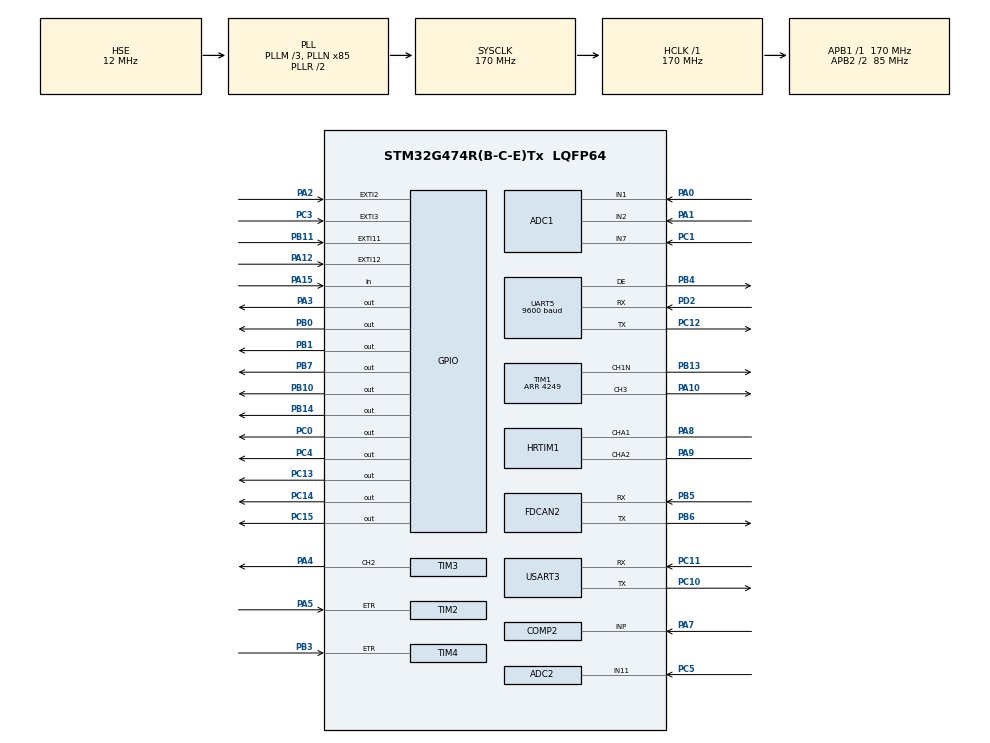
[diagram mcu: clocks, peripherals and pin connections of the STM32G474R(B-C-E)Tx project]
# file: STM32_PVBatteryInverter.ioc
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ADC1.Channel-0\#ChannelRegularConversion=ADC_CHANNEL_1
ADC1.Channel-1\#ChannelRegularConversion=ADC_CHANNEL_7
ADC1.DMAContinuousRequests=ENABLE
ADC1.EOCSelection=ADC_EOC_SEQ_CONV
ADC1.ExternalTrigConv=ADC_EXTERNALTRIG_HRTIM_TRG1
ADC1.NbrOfConversion=2
ADC1.NbrOfConversionFlag=1
ADC1.OffsetNumber-0\#ChannelRegularConversion=ADC_OFFSET_NONE
ADC1.OffsetNumber-1\#ChannelRegularConversion=ADC_OFFSET_NONE
ADC1.Overrun=ADC_OVR_DATA_OVERWRITTEN
ADC1.OversamplingMode=ENABLE
ADC1.Rank-0\#ChannelRegularConversion=1
ADC1.Rank-1\#ChannelRegularConversion=2
ADC1.Ratio=ADC_OVERSAMPLING_RATIO_8
ADC1.RightBitShift=ADC_RIGHTBITSHIFT_3
ADC1.SamplingTime-0\#ChannelRegularConversion=ADC_SAMPLETIME_2CYCLES_5
ADC1.SamplingTime-1\#ChannelRegularConversion=ADC_SAMPLETIME_2CYCLES_5
ADC1.SingleDiff-0\#ChannelRegularConversion=ADC_DIFFERENTIAL_ENDED
ADC1.master=1
ADC2.Channel-0\#ChannelRegularConversion=ADC_CHANNEL_11
ADC2.ClockPrescaler=ADC_CLOCK_SYNC_PCLK_DIV4
ADC2.DMAContinuousRequests=ENABLE
ADC2.ExternalTrigConv=ADC_SOFTWARE_START
ADC2.NbrOfConversion=1
ADC2.NbrOfConversionFlag=1
ADC2.OffsetNumber-0\#ChannelRegularConversion=ADC_OFFSET_NONE
ADC2.Overrun=ADC_OVR_DATA_OVERWRITTEN
ADC2.OversamplingMode=ENABLE
ADC2.Rank-0\#ChannelRegularConversion=1
ADC2.Ratio=ADC_OVERSAMPLING_RATIO_128
ADC2.RightBitShift=ADC_RIGHTBITSHIFT_3
ADC2.SamplingTime-0\#ChannelRegularConversion=ADC_SAMPLETIME_2CYCLES_5
COMP2.TriggerMode=COMP_TRIGGERMODE_IT_FALLING
Dma.ADC1.1.Direction=DMA_PERIPH_TO_MEMORY
Dma.ADC1.1.EventEnable=DISABLE
Dma.ADC1.1.Instance=DMA1_Channel2
Dma.ADC1.1.MemDataAlignment=DMA_MDATAALIGN_HALFWORD
Dma.ADC1.1.MemInc=DMA_MINC_ENABLE
Dma.ADC1.1.Mode=DMA_CIRCULAR
Dma.ADC1.1.PeriphDataAlignment=DMA_PDATAALIGN_HALFWORD
Dma.ADC1.1.PeriphInc=DMA_PINC_DISABLE
Dma.ADC1.1.Polarity=HAL_DMAMUX_REQ_GEN_RISING
Dma.ADC1.1.Priority=DMA_PRIORITY_LOW
Dma.ADC1.1.RequestNumber=1
Dma.ADC1.1.SignalID=NONE
Dma.ADC1.1.SyncEnable=DISABLE
Dma.ADC1.1.SyncPolarity=HAL_DMAMUX_SYNC_NO_EVENT
Dma.ADC1.1.SyncRequestNumber=1
Dma.ADC1.1.SyncSignalID=NONE
Dma.ADC2.0.Direction=DMA_PERIPH_TO_MEMORY
Dma.ADC2.0.EventEnable=DISABLE
Dma.ADC2.0.Instance=DMA1_Channel1
Dma.ADC2.0.MemDataAlignment=DMA_MDATAALIGN_HALFWORD
Dma.ADC2.0.MemInc=DMA_MINC_ENABLE
Dma.ADC2.0.Mode=DMA_CIRCULAR
Dma.ADC2.0.PeriphDataAlignment=DMA_PDATAALIGN_HALFWORD
Dma.ADC2.0.PeriphInc=DMA_PINC_DISABLE
Dma.ADC2.0.Polarity=HAL_DMAMUX_REQ_GEN_RISING
Dma.ADC2.0.Priority=DMA_PRIORITY_LOW
Dma.ADC2.0.RequestNumber=1
Dma.ADC2.0.SignalID=NONE
Dma.ADC2.0.SyncEnable=DISABLE
Dma.ADC2.0.SyncPolarity=HAL_DMAMUX_SYNC_NO_EVENT
Dma.ADC2.0.SyncRequestNumber=1
Dma.ADC2.0.SyncSignalID=NONE
Dma.Request0=ADC2
Dma.Request1=ADC1
Dma.Request2=USART3_TX
Dma.Request3=UART5_TX
Dma.Request4=UART5_RX
Dma.UART5_RX.4.Direction=DMA_PERIPH_TO_MEMORY
Dma.UART5_RX.4.EventEnable=DISABLE
Dma.UART5_RX.4.Instance=DMA1_Channel5
Dma.UART5_RX.4.MemDataAlignment=DMA_MDATAALIGN_BYTE
Dma.UART5_RX.4.MemInc=DMA_MINC_ENABLE
Dma.UART5_RX.4.Mode=DMA_NORMAL
Dma.UART5_RX.4.PeriphDataAlignment=DMA_PDATAALIGN_BYTE
Dma.UART5_RX.4.PeriphInc=DMA_PINC_DISABLE
Dma.UART5_RX.4.Polarity=HAL_DMAMUX_REQ_GEN_RISING
Dma.UART5_RX.4.Priority=DMA_PRIORITY_LOW
Dma.UART5_RX.4.RequestNumber=1
Dma.UART5_RX.4.SignalID=NONE
Dma.UART5_RX.4.SyncEnable=DISABLE
Dma.UART5_RX.4.SyncPolarity=HAL_DMAMUX_SYNC_NO_EVENT
Dma.UART5_RX.4.SyncRequestNumber=1
Dma.UART5_RX.4.SyncSignalID=NONE
Dma.UART5_TX.3.Direction=DMA_MEMORY_TO_PERIPH
Dma.UART5_TX.3.EventEnable=DISABLE
Dma.UART5_TX.3.Instance=DMA1_Channel4
Dma.UART5_TX.3.MemDataAlignment=DMA_MDATAALIGN_BYTE
Dma.UART5_TX.3.MemInc=DMA_MINC_ENABLE
Dma.UART5_TX.3.Mode=DMA_NORMAL
Dma.UART5_TX.3.PeriphDataAlignment=DMA_PDATAALIGN_BYTE
Dma.UART5_TX.3.PeriphInc=DMA_PINC_DISABLE
Dma.UART5_TX.3.Polarity=HAL_DMAMUX_REQ_GEN_RISING
Dma.UART5_TX.3.Priority=DMA_PRIORITY_LOW
Dma.UART5_TX.3.RequestNumber=1
Dma.UART5_TX.3.SignalID=NONE
Dma.UART5_TX.3.SyncEnable=DISABLE
Dma.UART5_TX.3.SyncPolarity=HAL_DMAMUX_SYNC_NO_EVENT
Dma.UART5_TX.3.SyncRequestNumber=1
Dma.UART5_TX.3.SyncSignalID=NONE
Dma.USART3_TX.2.Direction=DMA_MEMORY_TO_PERIPH
Dma.USART3_TX.2.EventEnable=DISABLE
Dma.USART3_TX.2.Instance=DMA1_Channel3
Dma.USART3_TX.2.MemDataAlignment=DMA_MDATAALIGN_BYTE
Dma.USART3_TX.2.MemInc=DMA_MINC_ENABLE
Dma.USART3_TX.2.Mode=DMA_NORMAL
Dma.USART3_TX.2.PeriphDataAlignment=DMA_PDATAALIGN_BYTE
Dma.USART3_TX.2.PeriphInc=DMA_PINC_DISABLE
Dma.USART3_TX.2.Polarity=HAL_DMAMUX_REQ_GEN_RISING
Dma.USART3_TX.2.Priority=DMA_PRIORITY_LOW
Dma.USART3_TX.2.RequestNumber=1
Dma.USART3_TX.2.SignalID=NONE
Dma.USART3_TX.2.SyncEnable=DISABLE
Dma.USART3_TX.2.SyncPolarity=HAL_DMAMUX_SYNC_NO_EVENT
Dma.USART3_TX.2.SyncRequestNumber=1
Dma.USART3_TX.2.SyncSignalID=NONE
FDCAN2.CalculateBaudRateNominal=500000
FDCAN2.CalculateTimeBitNominal=2000
FDCAN2.CalculateTimeQuantumNominal=400.0
FDCAN2.Mode=FDCAN_MODE_NORMAL
FDCAN2.NominalPrescaler=68
FDCAN2.StdFiltersNbr=2
HRTIM1.ADCTrigger1_Source1=HRTIM_ADCTRIGGEREVENT13_TIMERA_CMP3
HRTIM1.ADCTrigger_Id1=HRTIM_ADCTRIGGER_1
HRTIM1.Adrom_TA=HRTIM_TIM_ADROM_CREST
HRTIM1.CompareUnit1-Output_TA1TA2=HRTIM_COMPAREUNIT_1
HRTIM1.CompareUnit3-Output_TA1TA2=HRTIM_COMPAREUNIT_3
HRTIM1.CompareValue1-Output_TA1TA2=4250
HRTIM1.CompareValue3-Output_TA1TA2=8020
HRTIM1.Configuration_TA=Waveform
HRTIM1.Deadtimeconfig-Output_TA1TA2=__NULL
HRTIM1.Event_EEV1=__NULL
HRTIM1.GreaterCMP1_TA=HRTIM_TIMERGTCMP1_EQUAL
HRTIM1.GreaterCMP3_TA=HRTIM_TIMERGTCMP3_EQUAL
HRTIM1.NumberADCTriggerSource1=1
HRTIM1.NumberResetSource1-Output_TA1TA2=0
HRTIM1.NumberResetSource2_TA=0
HRTIM1.NumberSetSource1-Output_TA1TA2=1
HRTIM1.NumberSetSource2_TA=1
HRTIM1.Outrom_TA=HRTIM_TIM_OUTROM_BOTH
HRTIM1.Periode_TA=8500
HRTIM1.Polarity1-Output_TA1TA2=HRTIM_OUTPUTPOLARITY_LOW
HRTIM1.Polarity2-Output_TA1TA2=HRTIM_OUTPUTPOLARITY_HIGH
HRTIM1.PreloadEnable-Output_TA1TA2=HRTIM_PRELOAD_ENABLED
HRTIM1.PrescalerRatio_TA=HRTIM_PRESCALERRATIO_MUL2
HRTIM1.ReSyncUpdate-Output_TA1TA2=HRTIM_TIMERESYNC_UPDATE_CONDITIONAL
HRTIM1.RepetitionUpdate-Output_TA1TA2=HRTIM_UPDATEONREPETITION_ENABLED
HRTIM1.SetOutput1_Source1-Output_TA1TA2=HRTIM_OUTPUTSET_TIMCMP1
HRTIM1.SetOutput2_Source1-Output_TA1TA2=HRTIM_OUTPUTSET_TIMCMP1
HRTIM1.UpDownMode-Output_TA1TA2=HRTIM_TIMERUPDOWNMODE_UPDOWN
HRTIM1.postscaler1=0x0
HRTIM1.rom_TA=HRTIM_TIM_ROM_BOTH
IWDG.Prescaler=IWDG_PRESCALER_8
LPTIM1.ClockPrescaler=LPTIM_PRESCALER_DIV128
Mcu.Family=STM32G4
Mcu.Name=STM32G474R(B-C-E)Tx
Mcu.Package=LQFP64
NVIC.ADC1_2_IRQn=true\:0\:0\:false\:false\:true\:true\:true\:true
NVIC.COMP1_2_3_IRQn=true\:0\:0\:false\:false\:true\:false\:true\:true
NVIC.DMA1_Channel1_IRQn=true\:0\:0\:false\:false\:true\:false\:true\:true
NVIC.DMA1_Channel2_IRQn=true\:0\:0\:false\:false\:true\:false\:true\:true
NVIC.DMA1_Channel3_IRQn=true\:5\:0\:true\:false\:true\:false\:true\:true
NVIC.DMA1_Channel4_IRQn=true\:5\:0\:true\:false\:true\:false\:true\:true
NVIC.DMA1_Channel5_IRQn=true\:5\:0\:true\:false\:true\:false\:true\:true
NVIC.EXTI15_10_IRQn=true\:0\:0\:false\:false\:true\:true\:true\:true
NVIC.EXTI2_IRQn=true\:0\:0\:false\:false\:true\:true\:true\:true
NVIC.EXTI3_IRQn=true\:0\:0\:false\:false\:true\:true\:true\:true
NVIC.FDCAN2_IT0_IRQn=true\:4\:0\:true\:false\:true\:true\:true\:true
NVIC.FDCAN2_IT1_IRQn=true\:4\:0\:true\:false\:true\:true\:true\:true
NVIC.LPTIM1_IRQn=true\:5\:0\:true\:false\:true\:true\:true\:true
NVIC.PriorityGroup=NVIC_PRIORITYGROUP_4
NVIC.TIM1_TRG_COM_TIM17_IRQn=true\:0\:0\:false\:false\:true\:true\:true\:true
NVIC.UART5_IRQn=true\:4\:0\:true\:false\:true\:true\:true\:true
NVIC.USART3_IRQn=true\:4\:0\:true\:false\:true\:true\:true\:true
PA0.Mode=IN1-Differential
PA0.Signal=ADC1_IN1
PA1.Mode=IN1-Differential
PA1.Signal=ADC1_IN2
PA10.Signal=S_TIM1_CH3
PA11.Signal=FDCAN1_RX
PA12.GPIO_ModeDefaultEXTI=GPIO_MODE_IT_RISING
PA12.GPIO_PuPd=GPIO_PULLUP
PA12.Signal=GPXTI12
PA13.Mode=Serial_Wire
PA13.Signal=SYS_JTMS-SWDIO
PA14.Mode=Serial_Wire
PA14.Signal=SYS_JTCK-SWCLK
PA15.GPIO_PuPd=GPIO_PULLDOWN
PA15.Signal=GPIO_Input
PA2.GPIO_ModeDefaultEXTI=GPIO_MODE_IT_FALLING
PA2.Signal=GPXTI2
PA3.Signal=GPIO_Output
PA4.Signal=S_TIM3_CH2
PA5.Signal=S_TIM2_ETR
PA6.Signal=ADC2_IN3
PA7.Mode=INP
PA7.Signal=COMP2_INP
PA8.Mode=Output_TA1TA2
PA8.Signal=HRTIM1_CHA1
PA9.Mode=Output_TA1TA2
PA9.Signal=HRTIM1_CHA2
PB0.Signal=GPIO_Output
PB1.Signal=GPIO_Output
PB10.Signal=GPIO_Output
PB11.GPIO_ModeDefaultEXTI=GPIO_MODE_IT_RISING
PB11.GPIO_PuPd=GPIO_PULLUP
PB11.Signal=GPXTI11
PB13.Mode=PWM Generation1 CH1N
PB13.Signal=TIM1_CH1N
PB14.Signal=GPIO_Output
PB15.Signal=TIM1_CH3N
PB2.Signal=ADC2_IN12
PB3.Signal=S_TIM4_ETR
PB4.Mode=Hardware Flow Control (RS485)
PB4.Signal=UART5_DE
PB5.Mode=FDCAN_Activate
PB5.Signal=FDCAN2_RX
PB6.Mode=FDCAN_Activate
PB6.Signal=FDCAN2_TX
PB7.Signal=GPIO_Output
PB9.Signal=FDCAN1_TX
PC0.Signal=GPIO_Output
PC1.Mode=IN7-Single-Ended
PC1.Signal=ADC1_IN7
PC10.Mode=Asynchronous
PC10.Signal=USART3_TX
PC11.Mode=Asynchronous
PC11.Signal=USART3_RX
PC12.Mode=Asynchronous
PC12.Signal=UART5_TX
PC13.Signal=GPIO_Output
PC14-OSC32_IN.Signal=GPIO_Output
PC15-OSC32_OUT.Signal=GPIO_Output
PC3.GPIO_ModeDefaultEXTI=GPIO_MODE_IT_FALLING
PC3.Signal=GPXTI3
PC4.Signal=GPIO_Output
PC5.Mode=IN11-Single-Ended
PC5.Signal=ADC2_IN11
PC6.Signal=HRTIM1_CHF1
PC7.Signal=HRTIM1_CHF2
PC8.Signal=HRTIM1_CHE1
PC9.Signal=HRTIM1_CHE2
PD2.Mode=Asynchronous
PD2.Signal=UART5_RX
PF0-OSC_IN.Mode=HSE-External-Oscillator
PF0-OSC_IN.Signal=RCC_OSC_IN
PF1-OSC_OUT.Mode=HSE-External-Oscillator
PF1-OSC_OUT.Signal=RCC_OSC_OUT
ProjectManager.HeapSize=0x200
ProjectManager.StackSize=0x400
ProjectManager.TargetToolchain=STM32CubeIDE
RCC.ADC12Freq_Value=170000000
RCC.ADC345Freq_Value=170000000
RCC.AHBFreq_Value=170000000
RCC.APB1Freq_Value=170000000
RCC.APB1TimFreq_Value=170000000
RCC.APB2CLKDivider=RCC_HCLK_DIV2
RCC.APB2Freq_Value=85000000
RCC.APB2TimFreq_Value=170000000
RCC.CortexFreq_Value=170000000
RCC.EXTERNAL_CLOCK_VALUE=12288000
RCC.HCLKFreq_Value=170000000
RCC.HSE_VALUE=12000000
RCC.HSI48_VALUE=48000000
RCC.HSI_VALUE=16000000
RCC.LPTIM1CLockSelection=RCC_LPTIM1CLKSOURCE_LSI
RCC.LSE_VALUE=32768
RCC.PLLM=RCC_PLLM_DIV3
RCC.PLLN=85
RCC.PLLSourceVirtual=RCC_PLLSOURCE_HSE
RCC.SYSCLKFreq_VALUE=170000000
RCC.SYSCLKSource=RCC_SYSCLKSOURCE_PLLCLK
RCC.USBFreq_Value=170000000
RCC.VCOOutputFreq_Value=340000000
SH.S_TIM1_CH3.0=TIM1_CH3,PWM Generation3 CH3
SH.S_TIM2_ETR.0=TIM2_ETR,ClockSourceETR_Mode2
SH.S_TIM3_CH2.0=TIM3_CH2,PWM Generation2 CH2
SH.S_TIM4_ETR.0=TIM4_ETR,ClockSourceETR_Mode2
TIM1.Channel-PWM\ Generation1\ CH1N=TIM_CHANNEL_1
TIM1.Channel-PWM\ Generation3\ CH3=TIM_CHANNEL_3
TIM1.CounterMode=TIM_COUNTERMODE_CENTERALIGNED1
TIM1.OCNPolarity_1=TIM_OCNPOLARITY_LOW
TIM1.PeriodNoDither=4249
TIM1.RepetitionCounter=1
TIM1.TIM_MasterOutputTrigger=TIM_TRGO_UPDATE
TIM3.Channel-PWM\ Generation1\ CH1=TIM_CHANNEL_1
TIM3.Channel-PWM\ Generation2\ CH2=TIM_CHANNEL_2
UART5.BaudRate=9600
UART5.FIFOMode=FIFOMODE_ENABLE
UART5.RXFIFOThreshold=RXFIFO_THRESHOLD_1QUARTERFULL
UART5.TXFIFOThreshold=TXFIFO_THRESHOLD_1EIGHTHFULL
USART3.FIFOMode=FIFOMODE_ENABLE
USART3.VirtualMode-Asynchronous=VM_ASYNC
VP_COMP2_VS_VREFINT.Mode=VREFINT
VP_IWDG_VS_IWDG.Mode=IWDG_Activate
VP_LPTIM1_VS_LPTIM_counterModeInternalClock.Mode=Counts__internal_clock_event_00
VP_SYS_VS_DBSignals.Mode=DisableDeadBatterySignals
board=custom

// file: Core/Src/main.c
/* USER CODE BEGIN Header */
/**
  ******************************************************************************
  * @file           : main.c
  * @brief          : Main program body
  ******************************************************************************
  * @attention
  *
  * Copyright (c) 2023 STMicroelectronics.
  * All rights reserved.
  *
  * This software is licensed under terms that can be found in the LICENSE file
  * in the root directory of this software component.
  * If no LICENSE file comes with this software, it is provided AS-IS.
  *
  ******************************************************************************
  */
/* USER CODE END Header */
#include "main.h"

/* USER CODE BEGIN Includes */
#include <stdlib.h>
#include <stdbool.h>
#include <stdio.h>

#include <string.h>

#include "common.h"
#include "monitoring.h"
#include "gpio.h"
#include "can_bus.h"
#include "ac_control.h"
#include "dc_control.h"
#include "sys_mode_controller.h"
#include "BatteryManagement/bms_types.h"
#include "electricity_meter.h"
#include "power_controller.h"
#include "battery.h"
#include <sml/sml_crc16.h>
#include <modbus_hybridinverter.h>

// todo
typedef struct {
    uint16_t cell_voltage_max_mV;
    uint16_t cell_voltage_max_index;
    uint16_t cell_voltage_min_mV;
    uint16_t cell_voltage_min_index;
} __attribute__((__packed__)) csc_cell_volt_min_max_t;

/* USER CODE END Includes */

/* USER CODE BEGIN PD */
#define uSend(x) uartSend((char *)x, sizeof x -1)
/* USER CODE END PD */

ADC_HandleTypeDef hadc1;
ADC_HandleTypeDef hadc2;
DMA_HandleTypeDef hdma_adc1;
DMA_HandleTypeDef hdma_adc2;

COMP_HandleTypeDef hcomp2;

FDCAN_HandleTypeDef hfdcan2;

HRTIM_HandleTypeDef hhrtim1;

IWDG_HandleTypeDef hiwdg;

LPTIM_HandleTypeDef hlptim1;

TIM_HandleTypeDef htim1;
TIM_HandleTypeDef htim2;
TIM_HandleTypeDef htim3;
TIM_HandleTypeDef htim4;

UART_HandleTypeDef huart5;
UART_HandleTypeDef huart3;
DMA_HandleTypeDef hdma_uart5_tx;
DMA_HandleTypeDef hdma_uart5_rx;
DMA_HandleTypeDef hdma_usart3_tx;

/* USER CODE BEGIN PV */
char tx_buf[64];
uint8_t tx_len;

UART_HandleTypeDef* huart_rs485;
UART_HandleTypeDef* huart_debug;
mbus_t modbus;

uint16_t ADC1ConvertedData[2];
uint16_t ADC2ConvertedData[1];
volatile uint16_t debug_sigma_delta_re;

volatile uint16_t id;
control_ref_t ctrl_ref;
volatile bool print_request;

volatile uint32_t cnt_1Hz;
volatile uint32_t cntErr_1Hz;

volatile uint16_t debug_v_dc_FBboost_sincfilt_100mV;
volatile uint16_t debug_v_dc_FBgrid_sincfilt_100mV;

extern volatile int16_t debug_v_ac_rms_100mV;
#if SENSOR_CALIBRATION_MODE == 1
extern volatile int16_t debug_v_ac_100mV;
extern volatile int16_t debug_i_ac_10mA;
volatile int16_t debug_i_dc_filt_10mA;
#endif //SENSOR_CALIBRATION_MODE

extern volatile int16_t debug_i_ac_ref_amp_10mA;

uint8_t ubKeyNumber = 0x0;

/* USER CODE END PV */

void SystemClock_Config(void);
static void MX_GPIO_Init(void);
static void MX_DMA_Init(void);
static void MX_ADC1_Init(void);
static void MX_ADC2_Init(void);
static void MX_FDCAN2_Init(void);
static void MX_HRTIM1_Init(void);
static void MX_TIM1_Init(void);
static void MX_TIM2_Init(void);
static void MX_TIM3_Init(void);
static void MX_TIM4_Init(void);
static void MX_UART5_Init(void);
static void MX_USART3_UART_Init(void);
static void MX_IWDG_Init(void);
static void MX_LPTIM1_Init(void);
static void MX_COMP2_Init(void);
/* USER CODE BEGIN PFP */
static void FDCAN_Config(void);

/* USER CODE END PFP */

/* USER CODE BEGIN 0 */

void uartSend(char* ptr, int len)
{
    HAL_UART_Transmit(huart_debug, (uint8_t *)ptr,len, 10);
}

void uSendInt(int value)
{
	itoa(value, tx_buf, 10);
	tx_len=strlen(tx_buf);
	HAL_UART_Transmit(huart_debug, (uint8_t *)tx_buf, tx_len, 10);
}

void uSend_1m(int int_value)
{
	float value = int_value/1000.0;
	tx_len = snprintf(NULL, 0, "%.03f", value);
	char *str = (char *)malloc(tx_len + 1);
	snprintf(str, tx_len + 1, "%f.03", value);
	HAL_UART_Transmit(huart_debug, (uint8_t *)str, tx_len, 10);
	free(str);
}

void uSend_10m(int int_value)
{
	float value = int_value/100.0;
	tx_len = snprintf(NULL, 0, "%.02f", value);
	char *str = (char *)malloc(tx_len + 1);
	snprintf(str, tx_len + 1, "%f.02", value);
	HAL_UART_Transmit(huart_debug, (uint8_t *)str, tx_len, 10);
	free(str);
}

void uSend_100m(int int_value)
{
	float value = int_value/10.0;
	tx_len = snprintf(NULL, 0, "%.01f", value);
	char *str = (char *)malloc(tx_len + 1);
	snprintf(str, tx_len + 1, "%f.01", value);
	HAL_UART_Transmit(huart_debug, (uint8_t *)str, tx_len, 10);
	free(str);
}

int mbus_send(const mbus_t context, const uint8_t* data, const uint16_t size)
{
	// V1: blocking during send
	//HAL_Delay(1);
	if (HAL_UART_Transmit( huart_rs485, (uint8_t*) data, size, 1000) == HAL_OK) {
		return size;
	}

	// V2: use DMA
//	if (HAL_UART_Transmit_DMA( huart_rs485, (uint8_t*) data, size) == HAL_OK) {
//		return size;
//	}

	return 0;
}

void resetWatchdog()
{
	// Watchdog runs at 32/8=4kHz -> ~1sec for 4095
    /* Refresh IWDG: reload counter */
    if(HAL_IWDG_Refresh(&hiwdg) != HAL_OK) {
      /* Refresh Error */
      Error_Handler();
    }
}

void HAL_LPTIM_AutoReloadMatchCallback(LPTIM_HandleTypeDef *hlptim)
{
	cnt_1Hz++;
	if (get_sys_errorcode() != EC_NO_ERROR) {
		cntErr_1Hz++;
	}
}

void fill_monitor_vars_sys(monitor_vars_t* mon_vars)
{
	mon_vars->id = id;
	mon_vars->sys_mode = get_sys_mode();
	mon_vars->sys_errcode = get_sys_errorcode();

	fill_monitor_vars_dc(mon_vars);
	fill_monitor_vars_ac(mon_vars);

	mon_vars->ctrl_mode_AC = ctrl_ref.mode;
	mon_vars->p_ac_ref = ctrl_ref.p_ac_rms;

#if SYSTEM_HAS_BATTERY == 1
	const batteryStatus_t* battery = get_batteryStatus();
	mon_vars->bat_p = battery->power_W;
	mon_vars->soc_10mPercent = battery->soc_percent*100;
#endif //SYSTEM_HAS_BATTERY
}

#if COMM_READ_ELECTRICITY_METER == 1
// sends monitor_vars + header + crc via RS485
static void send_inverterdata()
{
	// if BMS is not part of the bus, add: Struct BMS Data : onoff Soc V I vmin vmax

	static monitor_packet_t mon_packet = {.header=0xDEADBEEF, 0};  // static for DMA
	fill_monitor_vars_sys(&mon_packet.monitor_vars);

	mon_packet.crc = sml_crc16_calculate((uint8_t *)&mon_packet.monitor_vars, sizeof(mon_packet.monitor_vars));

	if (HAL_UART_Transmit(huart_rs485, (uint8_t *)&mon_packet, sizeof(mon_packet), 10) != HAL_OK) {
		Error_Handler();
	}
//	if (HAL_UART_Transmit_DMA(huart_rs485, (uint8_t *)&mon_vars_snapshot, sizeof(mon_vars_snapshot)) != HAL_OK) {
//		Error_Handler();
//	}
}
#endif

void reinitUART(UART_HandleTypeDef *huart, uint32_t BaudRate)
{
	if (huart->Init.BaudRate != BaudRate) {
		huart->Init.BaudRate = BaudRate;
		if (HAL_UARTEx_DisableFifoMode(huart) != HAL_OK) {
			Error_Handler();
		}
		if (HAL_UART_Init(huart) != HAL_OK) {
			Error_Handler();
		}
		if (HAL_UARTEx_EnableFifoMode(huart) != HAL_OK) {
			Error_Handler();
		}
	}
}

void shutdownAll()
{
	gatedriverAC(0);
	gatedriverDC(0);
	contactorAC(0);
	contactorBattery(0);
#if SYSTEM_HAS_BATTERY == 1
	battery_state_request(CMD_BAT_OFF);  // todo: check CMD_BMS_OFF__BAT_OFF
#endif //SYSTEM_HAS_BATTERY
}

int el_meter_status;

void calc_and_wait(uint32_t delay)
{
	resetWatchdog();
	calc_async_dc_control();

#if COMM_READ_ELECTRICITY_METER == 0
	for (uint32_t i=0; i<delay; i++) {
		calc_async_dc_control();
		if (!monitoring_binary_en) {
			HAL_Delay(1);  //ms
		}
	}
#endif

#if COMM_READ_ELECTRICITY_METER == 1
	if (!monitoring_binary_en) {  // smart meter polling read takes too much time
		reinitUART(huart_rs485, 9600);
		resetWatchdog();
#define DUMMY_METER 0
#if DUMMY_METER == 1
		int el_meter_status = EL_METER_OKAY;
#else
		el_meter_status = electricity_meter_read(huart_rs485);
#endif //DUMMY_METER
		//HAL_UART_Abort_IT(&huart1);
		if ( el_meter_status == EL_METER_OKAY) {
			ctrl_ref.p_pcc_prev = ctrl_ref.p_pcc;
#if DUMMY_METER == 1
			const batteryStatus_t* battery = get_batteryStatus();
			//ctrl_ref.p_pcc = 50+battery->power_W;  // p_bat negative is discharging AC 4sec on 4sec off
			//ctrl_ref.p_pcc = 500;  // simulate load
			ctrl_ref.p_pcc = -100;  // simulate PV feedin
#else
			ctrl_ref.p_pcc = electricity_meter_get_power();
#endif //DUMMY_METER
#if SYSTEM_HAS_BATTERY == 1
			ctrl_ref.p_ac_pccCtrl = power_controller_step(modbus_reg_rw.p_pcc_ref_W, ctrl_ref.p_pcc, get_p_ac_max());
#endif //SYSTEM_HAS_BATTERY
		} else if (el_meter_status == EL_METER_CONN_ERR ) {
			ctrl_ref.p_ac_pccCtrl = 0;
		}

		if (el_meter_status == EL_METER_OKAY || el_meter_status == EL_METER_CONN_ERR ) {
			reinitUART(huart_rs485, 115200);
			calc_async_dc_control();

			if (async_battery_communication()) {
				send_inverterdata();

				// receive commands from external energy management system
//#define RX_MAX_CMD_LEN (sizeof("p_bat_chg_max65535\n")+5)
#define RX_MAX_CMD_LEN (sizeof(modbus_reg_rw_t)+8)
				uint8_t rx_buf[RX_MAX_CMD_LEN];

				for (uint16_t i = 0; i < 10; i++) {
					uint16_t rx_len = 0;
					HAL_UARTEx_ReceiveToIdle(huart_rs485, rx_buf, RX_MAX_CMD_LEN, &rx_len, 10);  // 10 x 10ms rx window

					for (uint16_t j = 0; j < rx_len; j++) {
						mbus_poll(modbus, rx_buf[j]);
					}
				}
				apply_sys_mode_cmd(&ctrl_ref);
				mbus_flush(modbus);  // reset incomplete messages
			}
		}
	} else {
		reinitUART(huart_rs485, 115200);
		resetWatchdog();
		calc_async_dc_control();
		async_battery_communication();
	}
#endif //COMM_READ_ELECTRICITY_METER

	calc_p_ac(&ctrl_ref);

	resetWatchdog();
	async_monitor_check(huart_debug);
}

// +-50A sensor range with 3.3V ADC:
// −62.1A to +32.1A
// analog watchdog: (dont use filtering in AWD1 because it does not work with sequence mode (scan conversion))
// oversampling is enabled (8xOSR; 3bit shift -> 4-(log2(8)/3 -1) = 4bit shift down
#define I_AC_AWD_THRESHOLD_HIGH ((E_I_AC_PULSE_MAX_AMP_10mA/IAC_RAW_TO_10mA + IAC_OFFSET_RAW)/16)
#define I_AC_AWD_THRESHOLD_LOW ((-E_I_AC_PULSE_MAX_AMP_10mA/IAC_RAW_TO_10mA + IAC_OFFSET_RAW)/16)
// for test
//#define I_AC_AWD_THRESHOLD_HIGH 208  // +16.0Ampere -> 1600/IAC_RAW_TO_10mA + 2632 = 3327 /16
//#define I_AC_AWD_THRESHOLD_LOW 121  // -16.0Ampere -> -1600/IAC_RAW_TO_10mA + 2632 = 1937 /16
//#define I_AC_AWD_THRESHOLD_HIGH 167  // +1.0Ampere -> 100/IAC_RAW_TO_10mA + 2632 = 2675 /16
//#define I_AC_AWD_THRESHOLD_LOW 162  // -1.0Ampere -> -100/IAC_RAW_TO_10mA + 2632 = 2589 /16
void HAL_ADC_LevelOutOfWindowCallback(ADC_HandleTypeDef* hadc)
{
	shutdownAll();
	set_sys_errorcode(EC_I_AC_PULSE_MAX);
}

void configure_analog_watchdog()
{
	/* Set ADC analog watchdog channels to be monitored */
	LL_ADC_SetAnalogWDMonitChannels(ADC1, LL_ADC_AWD1, LL_ADC_AWD_CHANNEL_7_REG);

	/* Set ADC analog watchdog thresholds */
	LL_ADC_ConfigAnalogWDThresholds(ADC1, LL_ADC_AWD1, I_AC_AWD_THRESHOLD_HIGH, I_AC_AWD_THRESHOLD_LOW);

	/*## Configuration of ADC interruptions ####################################*/
	// ADC1_2 interrupts are enabled in GUI
	/* Enable ADC analog watchdog 1 interruption */
	LL_ADC_EnableIT_AWD1(ADC1);
	LL_ADC_ClearFlag_AWD1(ADC1);
}

void HAL_ADC_ConvCpltCallback(ADC_HandleTypeDef *hadc)
{
	uint32_t start_ISR_cycles = DWT->CYCCNT;
	//static volatile uint16_t vdc_sinc_mix_100mV;
	static volatile uint16_t cnt20kHz_20ms = 0;

	/********************************************************/
	/* Highest priority: Grid control						*/
	/* 	execution rate: 20kHz								*/
	/* 	runtime: max18.4us									*/
	/*  max possible runtime without compare unit 3 change: */
	/*  25-5.1=19.9us										*/
	/********************************************************/

	// ADC1: two channels, Vac and i_ac
	// HRTIM1 triggers ADC once per period and DMA calls this callback if ADC1ConvertedData[2] is full
	// Thus, both channels in ADC1ConvertedData are updated in every call.
	if (hadc == &hadc1) {
		DEBUG_ISR GPIOC->BSRR = (1<<4);  // set Testpin TP201 PC4  T1
		// With 4xOversampling: 4.3us-0.44us=3.9us after mid of PWM period (see documentation/img folder)
		// With 8xOversampling: 7.0us-0.44us=6.6us after mid of PWM period -> 25-6.6=18.4us for calculation

		// start ADC2 conversion, because ADC1 conversions are complete here and can't be disturbed by ADC2
		LL_ADC_REG_StartConversion(hadc2.Instance);

//		if (fast_mon_vars_trig) {
//			if (frame_nr < FAST_MON_FRAMES) {
//				fast_monitor_vars[frame_nr].v_ac_100mV = ADC1ConvertedData[0];
//				fast_monitor_vars[frame_nr].i_ac_10mA = ADC1ConvertedData[1];
//				fast_monitor_vars[frame_nr].i_ac_ref_amp_10mA = ADC2ConvertedData[0]/16;
//				frame_nr++;
//			}
//		}

		measVdcFBgrid();  // if runtime becomes critical, run this line after ac dutycycle calculation

//#define V_AC_CALIB_OFFSET 1979 // Vin=0V offset=0.13V; Vin=313Vsine offset=0.87V
#define V_AC_CALIB_OFFSET 1982 // Vin=0V offset=-0.41V; Vin=313Vsine offset=0.1V
#define V_AC_CALIB_GAIN_PER_MIL 992
// 18.05.2026 Fluke multimeter
// V_AC_CALIB_OFFSET=1982  V_AC_CALIB_GAIN_PER_MIL=989
// 350.4V  shown as  349.1V to  349.3V
// -350.4V shown as -348.2V to -349.7V

		int v_ac_raw_no_calib = ADC1ConvertedData[0];
		int16_t v_ac_raw = ((v_ac_raw_no_calib-V_AC_CALIB_OFFSET)*V_AC_CALIB_GAIN_PER_MIL)/1000;

		//debug_v_ac_100mV = acControl_RAW_to_100mV(v_ac_raw);

		uint16_t i_ac_raw = ADC1ConvertedData[1];
		// Lowpass filter for Ig
//			static uint16_t Ig_prev[3] = {0};
//			uint16_t Ig_filt = lowpass4(i_ac_raw, Ig_prev);
		//debug_Ig_raw_filt = Ig_filt;

		uint16_t v_dc_FBboost_sincfilt_100mV = get_v_dc_FBboost_sincfilt_100mV();
		uint16_t v_dc_FBboost_filt50Hz_100mV = get_v_dc_FBboost_filt50Hz_100mV();
		int16_t duty = acControlStep(cnt20kHz_20ms, ctrl_ref, v_dc_FBboost_sincfilt_100mV, v_dc_FBboost_filt50Hz_100mV, v_ac_raw, i_ac_raw);
#if PWM_TEST_MODE == 1
		fan_control_test(1);
		duty = 4250;  // 50%
		//duty = 150;  // fixed duty for timing alignment test
		gatedriverAC(1);
#endif //PWM_TEST_MODE

		// set the PWM duty cycle value (into a 'shadow register')
		__HAL_HRTIM_SETCOMPARE(&hhrtim1, HRTIM_TIMERINDEX_TIMER_A, HRTIM_COMPAREUNIT_1, duty);

		// copy the PWM duty cycle value from the 'shadow register' to the 'active register' -> done by hardware
		//HAL_HRTIM_SoftwareUpdate(&hhrtim1, HRTIM_TIMERUPDATE_A);
		DEBUG_ISR GPIOC->BRR = (1<<4);  // reset Testpin TP201 PC4  T2: max18.2us after T1 (during meas of T2-T3 ~17.0us)

		/****************************************************/
		/* Lower priority: regular error checking			*/
		/* 	current errors are checked by analog watchdog 	*/
		/* 	execution rate: 40kHz							*/
		/* 	runtime in normal operation: ~2.1us				*/
		/* 	runtime in error case: ~3.1us					*/
		/****************************************************/
		checkErrors();
		static uint32_t blankingCnt = 0;

		if (blankingCnt > 240) {  // dont check sigmadelta data during startup for 240/20kHz/3ADCs = 4ms
			errorPVBI_t limitErr = checkDCLimits();
			if (limitErr != EC_NO_ERROR) {
				shutdownAll();
				set_sys_errorcode(limitErr);
			}
			limitErr = checkACLimits();
			if (limitErr != EC_NO_ERROR) {
				shutdownAll();  // todo shutdown AC only
				set_sys_errorcode(limitErr);
			}
		} else {
			blankingCnt++;
		}

		/********************************************/
		/* Lowest priority: DC stage control		*/
		/* 	DC voltage regulation and MPP tracking	*/
		/* 	runtime: ~5.8 to 8.9us					*/
		/********************************************/

		// 128x oversampling takes 128x(2.5+12.5) @ 170/4=42.5MHz -> 45.18us
		//if (hadc == &hadc2) {  // we take the most recent conversion of ADC2; timing alignment is not critical
		// called with f=40kHz when repetition counter = 0 -> for double current sense
		// called with f=20kHz when repetition counter = 1 -> for single current sense or hardware oversampling
		//
		// In interleaved DCDC booster with diodes, discontinuous current can occur -> Sampling the whole period is necessary
		// fadc = 170MHz/4 = 42.5MHz
		// cycles = 2.5+12.5 = 15
		// fsample = 42.5MHz/15 = 2.833Msamples/s
		// oversampling 128 -> 22.135kHz
		// todo: 22kHz vs 20kHz : no exact average current, but robust for MPPT and much better in discontinuous mode than double sample
		//	update: reduced analog filter BW to 7kHz, thus, discontinuous current should be filtered already in the analog domain
		//	update 25.11.2025: reduced analog filter BW to 1.26kHz
		DEBUG_ISR GPIOC->BSRR = (1<<4);  // set Testpin TP201 PC4  T3: ~19.1us after T1

		measVdcFBboost();

#define CNT_I_DC_AVG 16  // +3bit in hardware
		int16_t i_dc_filt_10mA = (ADC2ConvertedData[0]-CNT_I_DC_AVG*IDC_OFFSET_RAW)/CNT_I_DC_AVG * IDC_RAW_TO_10mA;
#if SENSOR_CALIBRATION_MODE == 1
		debug_i_dc_filt_10mA = i_dc_filt_10mA;
#endif //SENSOR_CALIBRATION_MODE

		cnt20kHz_20ms++;

		if (cnt20kHz_20ms >= CYCLES_cnt20kHz_20ms ) {
			id++;
			cnt20kHz_20ms = 0;

			static uint16_t cnt50Hz_1s = 0;
			cnt50Hz_1s++;
			if (cnt50Hz_1s >= 50 ) {
				cnt50Hz_1s = 0;
				battery_update_request();
				print_request = true;
			}
		}

		int16_t dutyHS = dcControlStep(cnt20kHz_20ms, ctrl_ref.v_dc_100mV, i_dc_filt_10mA, ctrl_ref.ext_dc_lock);

		int16_t dutyB1 = DEF_MPPT_DUTY_ABSMAX;  // Highside switch on
		int16_t dutyB2 = DEF_MPPT_DUTY_ABSMAX;  // Highside switch on

		switch(dcdc_mode) {
			case DCDC_HB1:
				dutyB1 = dutyHS;
				break;

			case DCDC_HB2:
				dutyB2 = dutyHS;
				break;

			case DCDC_INTERLEAVED:
				dutyB1 = dutyHS;
				dutyB2 = dutyHS;
				break;

			default:
				dutyB1 = dutyHS;
				break;
		}

#if PWM_TEST_MODE == 1
		dutyB1 = DEF_MPPT_DUTY_ABSMAX/2;
		dutyB2 = DEF_MPPT_DUTY_ABSMAX/2;
		gatedriverDC(1);
#elif PWM_TEST_MODE == 2
		dutyB2 = (0.9*DEF_MPPT_DUTY_ABSMAX);
		static uint16_t test_mode_cnt = 0;
		if (test_mode_cnt <= 2) {
			gatedriverDC(1);
			test_mode_cnt++;
		} else {
			GPIOB->BRR = (1<<7);  // disable boost gatedriver
			set_sys_errorcode(EC_TEST_COMPLETE);
		}
#endif //PWM_TEST_MODE

		__HAL_TIM_SetCompare(&htim1, TIM_CHANNEL_3, dutyB1);  // update pwm value
		__HAL_TIM_SetCompare(&htim1, TIM_CHANNEL_1, DEF_MPPT_DUTY_ABSMAX-dutyB2);

		uint32_t isr_cycles = DWT->CYCCNT - start_ISR_cycles;
#define ISR_CYC_LIMIT  (0.99*170000/20)  // 99% of 170MHz/20kHz; 98% triggers error; Idea allow 101% for one of two cycles and others only 97%
		if (isr_cycles > ISR_CYC_LIMIT) {
			shutdownAll();
			set_sys_errorcode(EC_ISR_RUNTIME_TOO_LONG);
		}

		DEBUG_ISR GPIOC->BRR = (1<<4);  // reset Testpin TP201 PC4  T4: ~27.2us after T1
    }
}

/* USER CODE END 0 */

int main(void)
{

  /* MCU Configuration--------------------------------------------------------*/

  /* Reset of all peripherals, Initializes the Flash interface and the Systick. */
  HAL_Init();

  /* Configure the system clock */
  SystemClock_Config();

  /* Initialize all configured peripherals */
  MX_GPIO_Init();
  MX_DMA_Init();
  MX_ADC1_Init();
  MX_ADC2_Init();
  MX_FDCAN2_Init();
  MX_HRTIM1_Init();
  MX_TIM1_Init();
  MX_TIM2_Init();
  MX_TIM3_Init();
  MX_TIM4_Init();
  MX_UART5_Init();
  MX_USART3_UART_Init();
  MX_IWDG_Init();
  MX_LPTIM1_Init();
  MX_COMP2_Init();
  /* USER CODE BEGIN 2 */

  /* Configure the overcurrent watchdog */
  configure_analog_watchdog();

  /* Configure the cycle counter for ISR runtime check */
  CoreDebug->DEMCR |= CoreDebug_DEMCR_TRCENA_Msk; // Enable Trace and debug blocks
  DWT->CTRL |= DWT_CTRL_CYCCNTENA_Msk;          // Enable CYCCNT register

  // Test battery contactor
#if TEST_BATTERY_CONTACTOR_MODE == 1
  bmsPower(1);
  contactorBattery(1);
  set_sys_errorcode(EC_TEST_COMPLETE);  // prevent system operation
  while (1) {
	resetWatchdog();
  }
#endif

  /* Configure the FDCAN peripheral */
  FDCAN_Config();  // CAN2 is connected to Battery Cell Stack Controller CAN Bus

  /* Modbus interface */
  uint8_t modbus_tx_buf[STMODBUS_MAX_RESPONSE_SIZE] = {0};
  uint8_t modbus_rx_buf[STMODBUS_MAX_RESPONSE_SIZE] = {0};

  Modbus_Conf_t mb_config;
  mb_config.send = &mbus_send;
  mb_config.sendbuf = modbus_tx_buf;
  mb_config.sendbuf_sz = STMODBUS_MAX_RESPONSE_SIZE;
  mb_config.recvbuf = modbus_rx_buf;
  mb_config.recvbuf_sz = STMODBUS_MAX_RESPONSE_SIZE;
  modbus = mbus_hybridinverter_open(&mb_config);

// Set to 1 to swap UARTs for Modbus debugging without using RS485 transceivers
#if 0
  huart_rs485 = &huart3;
  huart_debug = &huart5;
#else  // production
  huart_rs485 = &huart5;  // binary communication
  huart_debug = &huart3;  // text messages
#endif

  // DCDC sw-freq: 20kHz 170MHz/20kHz = 8500 -> Period = 4249
  // DCDC ctrl-freq: 100Hz -> Repetition Counter = 200
  // Todo check ADC clock

  // ###########################
  // ### Timer configuration ###
  // ###########################

  // start PWM for PV boost Half-bridge 1 (PWMA)
  if (   HAL_TIM_PWM_Start(&htim1, TIM_CHANNEL_3) != HAL_OK) {
    /* PWM Generation Error */
    Error_Handler();
  }
  // start PWM for PV boost Half-bridge 2 (PWMB)
  if (  HAL_TIMEx_PWMN_Start(&htim1, TIM_CHANNEL_1) != HAL_OK) {
    /* PWM Generation Error */
    Error_Handler();
  }
  // start PWM timer for PV boost Full-bridge
  if (  HAL_TIM_Base_Start_IT(&htim1) != HAL_OK)
  {
    Error_Handler();
  }

  // start timer for 1Hz system timebase
  #define LPTIM_TICKS_PER_SEC (32000/128)  // timer has 32kHz oscillator and DIV128 -> 250Hz
  if (HAL_LPTIM_Counter_Start_IT(&hlptim1, LPTIM_TICKS_PER_SEC) != HAL_OK) {
    Error_Handler();
  }

  // start Sigma-delta-ADC counter for Vdc FB_boost
  HAL_TIM_Base_Start(&htim4);

  // start Sigma-delta-ADC counter for Vdc FB_grid
  HAL_TIM_Base_Start(&htim2);

  // start PWM timer for grid Full-bridge
  if (   HAL_HRTIM_WaveformOutputStart(&hhrtim1, HRTIM_OUTPUT_TA1+HRTIM_OUTPUT_TA2) != HAL_OK)
  {
    /* PWM Generation Error */
    Error_Handler();
  }

  // Shift ADC trigger for phase correct ADC sampling
  // ADC oversample 8x need to be shifted 4x (15/42.5MHz) = 1.41176us
  // one up-down PWM period counts 2x8500 in 50us
  // 1.41176us/50us * (2*8500) = 480
  // 8500-480=8020  // Set this value in GUI compare unit 3, then ISR starts execution 5.1us after CNT_MAX (period)
  // Without the extra compare unit (using period of TimerA for ADC trigger) is takes 6.6us until DMA triggers the HAL_ADC_ConvCpltCallback

  if (   HAL_HRTIM_WaveformCounterStart(&hhrtim1, HRTIM_TIMERID_TIMER_A) != HAL_OK)
  {
    /* PWM Generation Error */
    Error_Handler();
  }

  // #########################
  // ### DMA configuration ###
  // #########################
  if ( HAL_ADC_Start_DMA(&hadc1, (uint32_t *)ADC1ConvertedData, sizeof(ADC1ConvertedData)/sizeof(ADC1ConvertedData[0]))  != HAL_OK)
  {
    Error_Handler();
  }

  if ( HAL_ADC_Start_DMA(&hadc2, (uint32_t *)ADC2ConvertedData, sizeof(ADC2ConvertedData)/sizeof(ADC2ConvertedData[0]))  != HAL_OK)
  {
    Error_Handler();
  }

  //__HAL_TIM_SetCompare(&htim1, TIM_CHANNEL_3, 2125);  //update pwm value 50% dutycycle

  /* Start COMP2 for 5V undervoltage protection */
  // test with load resistor:
  // 15.6Ohm: 4.67 to 4.69V does not trigger
  // 13.3Ohm: 4.60 to 4.65V triggers comparator
  // 10Ohm: slow 20ms drop to 3.86V triggers comparator and caused sigmadelta sensor error when comparator was not active.
  if(HAL_COMP_Start(&hcomp2) != HAL_OK) {
    Error_Handler();
  }

  uSend("PVBattery Inverter  ");
  uSend(__DATE__ " ");
  uSend(__TIME__);
  uSend("\n");
  GPIOB->BSRR = (1<<0);  // disable red LED

#define I_AC_AWD_THRESHOLD_to_10mA(x) ((x*16-IAC_OFFSET_RAW)*IAC_RAW_TO_10mA)
  uSend("I_AC analog watchdog config:\n");
  uSend(" high: ");
  uSendInt(I_AC_AWD_THRESHOLD_HIGH);
  uSend(" = ");
  uSend_10m(I_AC_AWD_THRESHOLD_to_10mA(I_AC_AWD_THRESHOLD_HIGH));
  uSend(" A\n");
  uSend(" low:  ");
  uSendInt(I_AC_AWD_THRESHOLD_LOW);
  uSend(" = ");
  uSend_10m(I_AC_AWD_THRESHOLD_to_10mA(I_AC_AWD_THRESHOLD_LOW));
  uSend(" A\n\n");

  /*## Check if the system has resumed from IWDG reset ####################*/
  HAL_PWR_EnableBkUpAccess();  // for access to flags written by the bootloader

  //  if (__HAL_RCC_GET_FLAG(RCC_FLAG_IWDGRST) != 0x00u) {  // Does not work, because bootloader clears the flag
  if (TAMP->BKP0R == 0x57444721) {  // "WDG!"
    TAMP->BKP0R = 0;

    uSend("Watchdog caused reset!");
    uSend("\n");
    set_sys_errorcode(EC_WATCHDOG_RESET);  // prevent ongoing inverter turnon in case of software bug
    HAL_Delay(300);  //ms
  }
  /* Clear reset flags anyway */
  __HAL_RCC_CLEAR_RESET_FLAGS();

  bool uart_output_text = false;
  bool uart_input_text = true;

#if SENSOR_CALIBRATION_MODE == 1
  uart_output_text = true;
#endif //SENSOR_CALIBRATION_MODE

  /* USER CODE END 2 */

  /* Infinite loop */
  while (1)
  {

    /* USER CODE BEGIN 3 */

	checkErrors();
	if (get_sys_mode() != OFF) GPIOB->BRR = (1<<1);  // enable green LED
	calc_and_wait(250);  //ms
	calc_and_wait(250);  //ms
	GPIOB->BSRR = (1<<1);  // disable green LED
	calc_and_wait(250);  //ms

	sys_mode_ctrl_step(&ctrl_ref);

	// UART
	if (print_request && uart_output_text) {
		print_request = false;

		calc_and_wait(250);  //ms

#if 0  // debug print battery info
		/************************/
		/* print battery status */
		/************************/

#if SYSTEM_HAS_BATTERY == 1
		const batteryStatus_t* battery = get_batteryStatus();
#endif //SYSTEM_HAS_BATTERY

		uSend("\nBatteryStatus\n");

		for (int c=0; c<(4*14); c++) {

			uSend("Temp");
			if (c<=8)
				uSend(" ");
			uSendInt(c+1);
			uSend(" ");
			uSendInt(get_battery_temperature(c));
			uSend("\n");
		}

		uint8_t nr_cells_balancing = 0;

		if (battery->voltage_100mV != 0) {
			for (int c=0; c<96; c++) {
				if (c%12 == 0) uSend(" ");
				uSend("Vc");
				if (c<=8)
					uSend(" ");
				uSendInt(c+1);
				uSend(" ");
				uSend_1m(get_battery_vCell_mV(c));

				if (get_battery_balancingState(c)) {
					uSend(" balancing");
					nr_cells_balancing++;
				}
				uSend("\n");
			}
		}
		uSend("nr_cells_balancing ");
		uSendInt(nr_cells_balancing);
		uSend("\n");

		int16_t vCellDIFF_mV = battery->maxVcell_mV - battery->minVcell_mV;
		uSend("vCellDIFF_mV ");
		uSend_1m(vCellDIFF_mV);
		uSend("\n");

		for (int csc=0; csc<4;csc++) {
			if (get_battery_csc_err(csc)) {
				uSend("Err in CSC");
				uSendInt(csc+1);
				uSend("\n");
				for (uint8_t bit=0; bit<64; bit++) {
					if ( (1<<bit) & get_battery_csc_err(csc)) {
						const char* strerr = get_battery_csc_err_str(bit);
						tx_len=strlen(strerr);
						HAL_UART_Transmit(huart_debug, (uint8_t *)strerr, tx_len, 10);
						uSend("\n");
					}
				}
			}
		}
#endif

		if (get_sys_errorcode()!=EC_NO_ERROR) {
			uSend("E ");
			itoa(get_sys_errorcode(), tx_buf, 10);
			tx_len=strlen(tx_buf);
			HAL_UART_Transmit(huart_debug, (uint8_t *)tx_buf, tx_len, 10);
			uSend(" ");
			char * strerr = strerror(get_sys_errorcode());
			tx_len=strlen(strerr);
			HAL_UART_Transmit(huart_debug, (uint8_t *)strerr, tx_len, 10);
			uSend("\n");
		}

		uSend("\nS ");
		itoa(get_sys_mode(), tx_buf, 10);
		tx_len=strlen(tx_buf);
		HAL_UART_Transmit(huart_debug, (uint8_t *)tx_buf, tx_len, 10);

		uSend("\nDC ");
		itoa(stateDC, tx_buf, 10);
		tx_len=strlen(tx_buf);
		HAL_UART_Transmit(huart_debug, (uint8_t *)tx_buf, tx_len, 10);
#if SYSTEM_HAS_BATTERY == 1
		uSend(" Bat ");
		itoa(get_stateBattery(), tx_buf, 10);
		tx_len=strlen(tx_buf);
		HAL_UART_Transmit(huart_debug, (uint8_t *)tx_buf, tx_len, 10);
#endif //SYSTEM_HAS_BATTERY

		uSend("\nAC ");
		itoa(stateAC, tx_buf, 10);
		tx_len=strlen(tx_buf);
		HAL_UART_Transmit(huart_debug, (uint8_t *)tx_buf, tx_len, 10);
		uSend("; ");
		itoa(ctrl_ref.mode, tx_buf, 10);
		tx_len=strlen(tx_buf);
		HAL_UART_Transmit(huart_debug, (uint8_t *)tx_buf, tx_len, 10);
		uSend("\n");

#if SYSTEM_HAS_BATTERY == 1 && SYS_MODE != PV2AC
		uSend("Vbat ");
		uSend_100m(battery->voltage_100mV);
		uSend("  ");
		uSend_1m(battery->minVcell_mV);
		uSend("  ");
		uSend_1m(battery->maxVcell_mV);
		uSend("\n");

		uSend("Tmin");
		uSendInt(battery->minTemp);
		uSend("  Tmax");
		uSendInt(battery->maxTemp);
		uSend("\n");

		uSend("SoC ");
		uSend_1m(battery->soc_percent*1000);
		uSend("\n");

		uSend("Pb ");
		uSendInt(battery->power_W);
		uSend("\n");
#endif //SYSTEM_HAS_BATTERY

		uSend("Ppcc ");
		uSendInt(ctrl_ref.p_pcc);
		if (el_meter_status == EL_METER_CONN_ERR) {
			uSend(" connErr");
		} else if (el_meter_status == EL_METER_CONN_WARN) {
			uSend(" connWarn");
		}
		uSend("\n");

		uSend("Pac ");
		uSendInt(get_p_ac_filt50Hz());
		uSend("  v_filt50Hz ");
		uSend_100m(debug_v_ac_rms_100mV);
#if SENSOR_CALIBRATION_MODE == 1
		uSend("  v_ac ");
		uSend_100m(debug_v_ac_100mV);
		uSend("  i_ac ");
		uSend_10m(debug_i_ac_10mA);
#endif //SENSOR_CALIBRATION_MODE
		uSend("  rI ");
		uSend_10m(debug_i_ac_ref_amp_10mA);
		uSend("\n");

//		uSend("f_ac ");
//		uSend_10m(debug_f_ac_10mHz);
//		uSend(" Hz\n");

		uSend("vdc b ");
		uSend_100m(debug_v_dc_FBboost_sincfilt_100mV);
		uSend("  g ");
		uSend_100m(debug_v_dc_FBgrid_sincfilt_100mV);
		uSend("\n");

#if SENSOR_CALIBRATION_MODE == 1
		uSend("i_dc ");
		uSend_10m(debug_i_dc_filt_10mA);
		uSend("\n");
#endif //SENSOR_CALIBRATION_MODE

		//	// no current 4avg: 2632-2634
		//	// ~-1A : 2592  ->LSB 23,8mA;  ~+1A 2675
		//
		//	uSend("Vg_raw_filt ");
		//	itoa(debug_Vg_raw_filt, Tx_Buffer, 10);
		//	Tx_len=strlen(Tx_Buffer);
		//	HAL_UART_Transmit(huart_debug, (uint8_t *)Tx_Buffer, Tx_len, 10);
		//	uSend("\n");
		//	// no voltage 4avg: 1971-1982
		//	// +5V + an N  - an L: 1995-2005  5V/24=0,2V per LSB
		//	// -5V: 1955-1964
		//
		//
		//	uSend("Ig_raw_filt ");
		//	itoa(debug_Ig_raw_filt, Tx_Buffer, 10);
		//	Tx_len=strlen(Tx_Buffer);
		//	HAL_UART_Transmit(huart_debug, (uint8_t *)Tx_Buffer, Tx_len, 10);
		//	uSend("\n");
		//	// no current 4avg: 2627-2630
		//	// ~+1A 2671
	}

	// UART RX
	uint8_t rx_buf = 0;
	HAL_UART_Receive(huart_debug, &rx_buf, 1, 1);  // todo: watchdog is triggered if this line missing in monitor mode; seems fixed by enabling uart interrupt

	if (uart_input_text) {
		if (rx_buf == 'p') {
			uSend("Print ENABLE\n");
			uart_output_text = true;
		} else if (rx_buf == 'd') {
			uSend("Print DISABLE\n");
			uart_output_text = false;
			monitoring_binary_en = false;
		} else if (rx_buf == 'm') {
			uSend("Monitoring ENABLE\n");
			monitoring_binary_en = true;
			uart_output_text = false;
			//uart_input_text = false;
		} else if (rx_buf == 'f') {
			uSend("Fast monitor TRIG\n");
			monitoring_binary_en = false;
			fast_mon_vars_trig = true;
			uart_output_text = false;
//		} else if (rx_buf == 'c') {
//			uSend("Contactor Enable\n");
//			contactorBattery(1);
		} else if (rx_buf == 'b') {
			uSend("BALANCING ENABLE\n");
			battery_set_balancing(0b1111, 3650);  // all CSCs
		} else	if (rx_buf == 's') {
			uSend("BALANCING DISABLE\n");
			battery_set_balancing(0b0, 3600);
		}
	}

  }
  /* USER CODE END 3 */
}

void SystemClock_Config(void)
{
  RCC_OscInitTypeDef RCC_OscInitStruct = {0};
  RCC_ClkInitTypeDef RCC_ClkInitStruct = {0};

  /** Configure the main internal regulator output voltage
  */
  HAL_PWREx_ControlVoltageScaling(PWR_REGULATOR_VOLTAGE_SCALE1_BOOST);

  /** Initializes the RCC Oscillators according to the specified parameters
  * in the RCC_OscInitTypeDef structure.
  */
  RCC_OscInitStruct.OscillatorType = RCC_OSCILLATORTYPE_LSI|RCC_OSCILLATORTYPE_HSE;
  RCC_OscInitStruct.HSEState = RCC_HSE_ON;
  RCC_OscInitStruct.LSIState = RCC_LSI_ON;
  RCC_OscInitStruct.PLL.PLLState = RCC_PLL_ON;
  RCC_OscInitStruct.PLL.PLLSource = RCC_PLLSOURCE_HSE;
  RCC_OscInitStruct.PLL.PLLM = RCC_PLLM_DIV3;
  RCC_OscInitStruct.PLL.PLLN = 85;
  RCC_OscInitStruct.PLL.PLLP = RCC_PLLP_DIV2;
  RCC_OscInitStruct.PLL.PLLQ = RCC_PLLQ_DIV2;
  RCC_OscInitStruct.PLL.PLLR = RCC_PLLR_DIV2;
  if (HAL_RCC_OscConfig(&RCC_OscInitStruct) != HAL_OK)
  {
    Error_Handler();
  }

  /** Initializes the CPU, AHB and APB buses clocks
  */
  RCC_ClkInitStruct.ClockType = RCC_CLOCKTYPE_HCLK|RCC_CLOCKTYPE_SYSCLK
                              |RCC_CLOCKTYPE_PCLK1|RCC_CLOCKTYPE_PCLK2;
  RCC_ClkInitStruct.SYSCLKSource = RCC_SYSCLKSOURCE_PLLCLK;
  RCC_ClkInitStruct.AHBCLKDivider = RCC_SYSCLK_DIV1;
  RCC_ClkInitStruct.APB1CLKDivider = RCC_HCLK_DIV1;
  RCC_ClkInitStruct.APB2CLKDivider = RCC_HCLK_DIV2;

  if (HAL_RCC_ClockConfig(&RCC_ClkInitStruct, FLASH_LATENCY_4) != HAL_OK)
  {
    Error_Handler();
  }
}

static void MX_ADC1_Init(void)
{

  ADC_MultiModeTypeDef multimode = {0};
  ADC_ChannelConfTypeDef sConfig = {0};

  /** Common config
  */
  hadc1.Instance = ADC1;
  hadc1.Init.ClockPrescaler = ADC_CLOCK_SYNC_PCLK_DIV4;
  hadc1.Init.Resolution = ADC_RESOLUTION_12B;
  hadc1.Init.DataAlign = ADC_DATAALIGN_RIGHT;
  hadc1.Init.GainCompensation = 0;
  hadc1.Init.ScanConvMode = ADC_SCAN_ENABLE;
  hadc1.Init.EOCSelection = ADC_EOC_SEQ_CONV;
  hadc1.Init.LowPowerAutoWait = DISABLE;
  hadc1.Init.ContinuousConvMode = DISABLE;
  hadc1.Init.NbrOfConversion = 2;
  hadc1.Init.DiscontinuousConvMode = DISABLE;
  hadc1.Init.ExternalTrigConv = ADC_EXTERNALTRIG_HRTIM_TRG1;
  hadc1.Init.ExternalTrigConvEdge = ADC_EXTERNALTRIGCONVEDGE_RISING;
  hadc1.Init.DMAContinuousRequests = ENABLE;
  hadc1.Init.Overrun = ADC_OVR_DATA_OVERWRITTEN;
  hadc1.Init.OversamplingMode = ENABLE;
  hadc1.Init.Oversampling.Ratio = ADC_OVERSAMPLING_RATIO_8;
  hadc1.Init.Oversampling.RightBitShift = ADC_RIGHTBITSHIFT_3;
  hadc1.Init.Oversampling.TriggeredMode = ADC_TRIGGEREDMODE_SINGLE_TRIGGER;
  hadc1.Init.Oversampling.OversamplingStopReset = ADC_REGOVERSAMPLING_CONTINUED_MODE;
  if (HAL_ADC_Init(&hadc1) != HAL_OK)
  {
    Error_Handler();
  }

  /** Configure the ADC multi-mode
  */
  multimode.Mode = ADC_MODE_INDEPENDENT;
  if (HAL_ADCEx_MultiModeConfigChannel(&hadc1, &multimode) != HAL_OK)
  {
    Error_Handler();
  }

  /** Configure Regular Channel
  */
  sConfig.Channel = ADC_CHANNEL_1;
  sConfig.Rank = ADC_REGULAR_RANK_1;
  sConfig.SamplingTime = ADC_SAMPLETIME_2CYCLES_5;
  sConfig.SingleDiff = ADC_DIFFERENTIAL_ENDED;
  sConfig.OffsetNumber = ADC_OFFSET_NONE;
  sConfig.Offset = 0;
  if (HAL_ADC_ConfigChannel(&hadc1, &sConfig) != HAL_OK)
  {
    Error_Handler();
  }

  /** Configure Regular Channel
  */
  sConfig.Channel = ADC_CHANNEL_7;
  sConfig.Rank = ADC_REGULAR_RANK_2;
  sConfig.SingleDiff = ADC_SINGLE_ENDED;
  if (HAL_ADC_ConfigChannel(&hadc1, &sConfig) != HAL_OK)
  {
    Error_Handler();
  }

}

static void MX_ADC2_Init(void)
{

  ADC_ChannelConfTypeDef sConfig = {0};

  /** Common config
  */
  hadc2.Instance = ADC2;
  hadc2.Init.ClockPrescaler = ADC_CLOCK_SYNC_PCLK_DIV4;
  hadc2.Init.Resolution = ADC_RESOLUTION_12B;
  hadc2.Init.DataAlign = ADC_DATAALIGN_RIGHT;
  hadc2.Init.GainCompensation = 0;
  hadc2.Init.ScanConvMode = ADC_SCAN_DISABLE;
  hadc2.Init.EOCSelection = ADC_EOC_SINGLE_CONV;
  hadc2.Init.LowPowerAutoWait = DISABLE;
  hadc2.Init.ContinuousConvMode = DISABLE;
  hadc2.Init.NbrOfConversion = 1;
  hadc2.Init.DiscontinuousConvMode = DISABLE;
  hadc2.Init.ExternalTrigConv = ADC_SOFTWARE_START;
  hadc2.Init.ExternalTrigConvEdge = ADC_EXTERNALTRIGCONVEDGE_NONE;
  hadc2.Init.DMAContinuousRequests = ENABLE;
  hadc2.Init.Overrun = ADC_OVR_DATA_OVERWRITTEN;
  hadc2.Init.OversamplingMode = ENABLE;
  hadc2.Init.Oversampling.Ratio = ADC_OVERSAMPLING_RATIO_128;
  hadc2.Init.Oversampling.RightBitShift = ADC_RIGHTBITSHIFT_3;
  hadc2.Init.Oversampling.TriggeredMode = ADC_TRIGGEREDMODE_SINGLE_TRIGGER;
  hadc2.Init.Oversampling.OversamplingStopReset = ADC_REGOVERSAMPLING_CONTINUED_MODE;
  if (HAL_ADC_Init(&hadc2) != HAL_OK)
  {
    Error_Handler();
  }

  /** Configure Regular Channel
  */
  sConfig.Channel = ADC_CHANNEL_11;
  sConfig.Rank = ADC_REGULAR_RANK_1;
  sConfig.SamplingTime = ADC_SAMPLETIME_2CYCLES_5;
  sConfig.SingleDiff = ADC_SINGLE_ENDED;
  sConfig.OffsetNumber = ADC_OFFSET_NONE;
  sConfig.Offset = 0;
  if (HAL_ADC_ConfigChannel(&hadc2, &sConfig) != HAL_OK)
  {
    Error_Handler();
  }

}

static void MX_COMP2_Init(void)
{

  hcomp2.Instance = COMP2;
  hcomp2.Init.InputPlus = COMP_INPUT_PLUS_IO1;
  hcomp2.Init.InputMinus = COMP_INPUT_MINUS_VREFINT;
  hcomp2.Init.OutputPol = COMP_OUTPUTPOL_NONINVERTED;
  hcomp2.Init.Hysteresis = COMP_HYSTERESIS_NONE;
  hcomp2.Init.BlankingSrce = COMP_BLANKINGSRC_NONE;
  hcomp2.Init.TriggerMode = COMP_TRIGGERMODE_IT_FALLING;
  if (HAL_COMP_Init(&hcomp2) != HAL_OK)
  {
    Error_Handler();
  }

}

static void MX_FDCAN2_Init(void)
{

  hfdcan2.Instance = FDCAN2;
  hfdcan2.Init.ClockDivider = FDCAN_CLOCK_DIV1;
  hfdcan2.Init.FrameFormat = FDCAN_FRAME_CLASSIC;
  hfdcan2.Init.Mode = FDCAN_MODE_NORMAL;
  hfdcan2.Init.AutoRetransmission = DISABLE;
  hfdcan2.Init.TransmitPause = DISABLE;
  hfdcan2.Init.ProtocolException = DISABLE;
  hfdcan2.Init.NominalPrescaler = 68;
  hfdcan2.Init.NominalSyncJumpWidth = 1;
  hfdcan2.Init.NominalTimeSeg1 = 2;
  hfdcan2.Init.NominalTimeSeg2 = 2;
  hfdcan2.Init.DataPrescaler = 1;
  hfdcan2.Init.DataSyncJumpWidth = 1;
  hfdcan2.Init.DataTimeSeg1 = 1;
  hfdcan2.Init.DataTimeSeg2 = 1;
  hfdcan2.Init.StdFiltersNbr = 10;
  hfdcan2.Init.ExtFiltersNbr = 0;
  hfdcan2.Init.TxFifoQueueMode = FDCAN_TX_FIFO_OPERATION;
  if (HAL_FDCAN_Init(&hfdcan2) != HAL_OK)
  {
    Error_Handler();
  }

}

static void MX_HRTIM1_Init(void)
{

  HRTIM_ADCTriggerCfgTypeDef pADCTriggerCfg = {0};
  HRTIM_TimeBaseCfgTypeDef pTimeBaseCfg = {0};
  HRTIM_TimerCtlTypeDef pTimerCtl = {0};
  HRTIM_TimerCfgTypeDef pTimerCfg = {0};
  HRTIM_CompareCfgTypeDef pCompareCfg = {0};
  HRTIM_OutputCfgTypeDef pOutputCfg = {0};

  hhrtim1.Instance = HRTIM1;
  hhrtim1.Init.HRTIMInterruptResquests = HRTIM_IT_NONE;
  hhrtim1.Init.SyncOptions = HRTIM_SYNCOPTION_NONE;
  if (HAL_HRTIM_Init(&hhrtim1) != HAL_OK)
  {
    Error_Handler();
  }
  if (HAL_HRTIM_DLLCalibrationStart(&hhrtim1, HRTIM_CALIBRATIONRATE_3) != HAL_OK)
  {
    Error_Handler();
  }
  if (HAL_HRTIM_PollForDLLCalibration(&hhrtim1, 10) != HAL_OK)
  {
    Error_Handler();
  }
  pADCTriggerCfg.UpdateSource = HRTIM_ADCTRIGGERUPDATE_TIMER_A;
  pADCTriggerCfg.Trigger = HRTIM_ADCTRIGGEREVENT13_TIMERA_CMP3;
  if (HAL_HRTIM_ADCTriggerConfig(&hhrtim1, HRTIM_ADCTRIGGER_1, &pADCTriggerCfg) != HAL_OK)
  {
    Error_Handler();
  }
  if (HAL_HRTIM_ADCPostScalerConfig(&hhrtim1, HRTIM_ADCTRIGGER_1, 0x0) != HAL_OK)
  {
    Error_Handler();
  }
  pTimeBaseCfg.Period = 8500;
  pTimeBaseCfg.RepetitionCounter = 0x00;
  pTimeBaseCfg.PrescalerRatio = HRTIM_PRESCALERRATIO_MUL2;
  pTimeBaseCfg.Mode = HRTIM_MODE_CONTINUOUS;
  if (HAL_HRTIM_TimeBaseConfig(&hhrtim1, HRTIM_TIMERINDEX_TIMER_A, &pTimeBaseCfg) != HAL_OK)
  {
    Error_Handler();
  }
  pTimerCtl.UpDownMode = HRTIM_TIMERUPDOWNMODE_UPDOWN;
  pTimerCtl.GreaterCMP3 = HRTIM_TIMERGTCMP3_EQUAL;
  pTimerCtl.GreaterCMP1 = HRTIM_TIMERGTCMP1_EQUAL;
  pTimerCtl.DualChannelDacEnable = HRTIM_TIMER_DCDE_DISABLED;
  if (HAL_HRTIM_WaveformTimerControl(&hhrtim1, HRTIM_TIMERINDEX_TIMER_A, &pTimerCtl) != HAL_OK)
  {
    Error_Handler();
  }
  if (HAL_HRTIM_RollOverModeConfig(&hhrtim1, HRTIM_TIMERINDEX_TIMER_A, HRTIM_TIM_FEROM_BOTH|HRTIM_TIM_BMROM_BOTH
                              |HRTIM_TIM_ADROM_CREST|HRTIM_TIM_OUTROM_BOTH
                              |HRTIM_TIM_ROM_BOTH) != HAL_OK)
  {
    Error_Handler();
  }
  pTimerCfg.InterruptRequests = HRTIM_TIM_IT_NONE;
  pTimerCfg.DMARequests = HRTIM_TIM_DMA_NONE;
  pTimerCfg.DMASrcAddress = 0x0000;
  pTimerCfg.DMADstAddress = 0x0000;
  pTimerCfg.DMASize = 0x1;
  pTimerCfg.HalfModeEnable = HRTIM_HALFMODE_DISABLED;
  pTimerCfg.InterleavedMode = HRTIM_INTERLEAVED_MODE_DISABLED;
  pTimerCfg.StartOnSync = HRTIM_SYNCSTART_DISABLED;
  pTimerCfg.ResetOnSync = HRTIM_SYNCRESET_DISABLED;
  pTimerCfg.DACSynchro = HRTIM_DACSYNC_NONE;
  pTimerCfg.PreloadEnable = HRTIM_PRELOAD_ENABLED;
  pTimerCfg.UpdateGating = HRTIM_UPDATEGATING_INDEPENDENT;
  pTimerCfg.BurstMode = HRTIM_TIMERBURSTMODE_MAINTAINCLOCK;
  pTimerCfg.RepetitionUpdate = HRTIM_UPDATEONREPETITION_ENABLED;
  pTimerCfg.PushPull = HRTIM_TIMPUSHPULLMODE_DISABLED;
  pTimerCfg.FaultEnable = HRTIM_TIMFAULTENABLE_NONE;
  pTimerCfg.FaultLock = HRTIM_TIMFAULTLOCK_READWRITE;
  pTimerCfg.DeadTimeInsertion = HRTIM_TIMDEADTIMEINSERTION_DISABLED;
  pTimerCfg.DelayedProtectionMode = HRTIM_TIMER_A_B_C_DELAYEDPROTECTION_DISABLED;
  pTimerCfg.UpdateTrigger = HRTIM_TIMUPDATETRIGGER_NONE;
  pTimerCfg.ResetTrigger = HRTIM_TIMRESETTRIGGER_NONE;
  pTimerCfg.ResetUpdate = HRTIM_TIMUPDATEONRESET_DISABLED;
  pTimerCfg.ReSyncUpdate = HRTIM_TIMERESYNC_UPDATE_CONDITIONAL;
  if (HAL_HRTIM_WaveformTimerConfig(&hhrtim1, HRTIM_TIMERINDEX_TIMER_A, &pTimerCfg) != HAL_OK)
  {
    Error_Handler();
  }
  pCompareCfg.CompareValue = 4250;
  if (HAL_HRTIM_WaveformCompareConfig(&hhrtim1, HRTIM_TIMERINDEX_TIMER_A, HRTIM_COMPAREUNIT_1, &pCompareCfg) != HAL_OK)
  {
    Error_Handler();
  }
  pCompareCfg.CompareValue = 8020;
  if (HAL_HRTIM_WaveformCompareConfig(&hhrtim1, HRTIM_TIMERINDEX_TIMER_A, HRTIM_COMPAREUNIT_3, &pCompareCfg) != HAL_OK)
  {
    Error_Handler();
  }
  pOutputCfg.Polarity = HRTIM_OUTPUTPOLARITY_LOW;
  pOutputCfg.SetSource = HRTIM_OUTPUTSET_TIMCMP1;
  pOutputCfg.ResetSource = HRTIM_OUTPUTRESET_NONE;
  pOutputCfg.IdleMode = HRTIM_OUTPUTIDLEMODE_NONE;
  pOutputCfg.IdleLevel = HRTIM_OUTPUTIDLELEVEL_INACTIVE;
  pOutputCfg.FaultLevel = HRTIM_OUTPUTFAULTLEVEL_NONE;
  pOutputCfg.ChopperModeEnable = HRTIM_OUTPUTCHOPPERMODE_DISABLED;
  pOutputCfg.BurstModeEntryDelayed = HRTIM_OUTPUTBURSTMODEENTRY_REGULAR;
  if (HAL_HRTIM_WaveformOutputConfig(&hhrtim1, HRTIM_TIMERINDEX_TIMER_A, HRTIM_OUTPUT_TA1, &pOutputCfg) != HAL_OK)
  {
    Error_Handler();
  }
  pOutputCfg.Polarity = HRTIM_OUTPUTPOLARITY_HIGH;
  if (HAL_HRTIM_WaveformOutputConfig(&hhrtim1, HRTIM_TIMERINDEX_TIMER_A, HRTIM_OUTPUT_TA2, &pOutputCfg) != HAL_OK)
  {
    Error_Handler();
  }
  HAL_HRTIM_MspPostInit(&hhrtim1);

}

static void MX_IWDG_Init(void)
{

  hiwdg.Instance = IWDG;
  hiwdg.Init.Prescaler = IWDG_PRESCALER_8;
  hiwdg.Init.Window = 4095;
  hiwdg.Init.Reload = 4095;
  if (HAL_IWDG_Init(&hiwdg) != HAL_OK)
  {
    Error_Handler();
  }

}

static void MX_LPTIM1_Init(void)
{

  hlptim1.Instance = LPTIM1;
  hlptim1.Init.Clock.Source = LPTIM_CLOCKSOURCE_APBCLOCK_LPOSC;
  hlptim1.Init.Clock.Prescaler = LPTIM_PRESCALER_DIV128;
  hlptim1.Init.Trigger.Source = LPTIM_TRIGSOURCE_SOFTWARE;
  hlptim1.Init.OutputPolarity = LPTIM_OUTPUTPOLARITY_HIGH;
  hlptim1.Init.UpdateMode = LPTIM_UPDATE_IMMEDIATE;
  hlptim1.Init.CounterSource = LPTIM_COUNTERSOURCE_INTERNAL;
  hlptim1.Init.Input1Source = LPTIM_INPUT1SOURCE_GPIO;
  hlptim1.Init.Input2Source = LPTIM_INPUT2SOURCE_GPIO;
  if (HAL_LPTIM_Init(&hlptim1) != HAL_OK)
  {
    Error_Handler();
  }

}

static void MX_TIM1_Init(void)
{

  TIM_MasterConfigTypeDef sMasterConfig = {0};
  TIM_OC_InitTypeDef sConfigOC = {0};
  TIM_BreakDeadTimeConfigTypeDef sBreakDeadTimeConfig = {0};

  htim1.Instance = TIM1;
  htim1.Init.Prescaler = 0;
  htim1.Init.CounterMode = TIM_COUNTERMODE_CENTERALIGNED1;
  htim1.Init.Period = 4249;
  htim1.Init.ClockDivision = TIM_CLOCKDIVISION_DIV1;
  htim1.Init.RepetitionCounter = 1;
  htim1.Init.AutoReloadPreload = TIM_AUTORELOAD_PRELOAD_DISABLE;
  if (HAL_TIM_PWM_Init(&htim1) != HAL_OK)
  {
    Error_Handler();
  }
  sMasterConfig.MasterOutputTrigger = TIM_TRGO_UPDATE;
  sMasterConfig.MasterOutputTrigger2 = TIM_TRGO2_RESET;
  sMasterConfig.MasterSlaveMode = TIM_MASTERSLAVEMODE_DISABLE;
  if (HAL_TIMEx_MasterConfigSynchronization(&htim1, &sMasterConfig) != HAL_OK)
  {
    Error_Handler();
  }
  sConfigOC.OCMode = TIM_OCMODE_PWM1;
  sConfigOC.Pulse = 0;
  sConfigOC.OCPolarity = TIM_OCPOLARITY_HIGH;
  sConfigOC.OCNPolarity = TIM_OCNPOLARITY_LOW;
  sConfigOC.OCFastMode = TIM_OCFAST_DISABLE;
  sConfigOC.OCIdleState = TIM_OCIDLESTATE_RESET;
  sConfigOC.OCNIdleState = TIM_OCNIDLESTATE_RESET;
  if (HAL_TIM_PWM_ConfigChannel(&htim1, &sConfigOC, TIM_CHANNEL_1) != HAL_OK)
  {
    Error_Handler();
  }
  sConfigOC.OCNPolarity = TIM_OCNPOLARITY_HIGH;
  if (HAL_TIM_PWM_ConfigChannel(&htim1, &sConfigOC, TIM_CHANNEL_3) != HAL_OK)
  {
    Error_Handler();
  }
  sBreakDeadTimeConfig.OffStateRunMode = TIM_OSSR_DISABLE;
  sBreakDeadTimeConfig.OffStateIDLEMode = TIM_OSSI_DISABLE;
  sBreakDeadTimeConfig.LockLevel = TIM_LOCKLEVEL_OFF;
  sBreakDeadTimeConfig.DeadTime = 0;
  sBreakDeadTimeConfig.BreakState = TIM_BREAK_DISABLE;
  sBreakDeadTimeConfig.BreakPolarity = TIM_BREAKPOLARITY_HIGH;
  sBreakDeadTimeConfig.BreakFilter = 0;
  sBreakDeadTimeConfig.BreakAFMode = TIM_BREAK_AFMODE_INPUT;
  sBreakDeadTimeConfig.Break2State = TIM_BREAK2_DISABLE;
  sBreakDeadTimeConfig.Break2Polarity = TIM_BREAK2POLARITY_HIGH;
  sBreakDeadTimeConfig.Break2Filter = 0;
  sBreakDeadTimeConfig.Break2AFMode = TIM_BREAK_AFMODE_INPUT;
  sBreakDeadTimeConfig.AutomaticOutput = TIM_AUTOMATICOUTPUT_DISABLE;
  if (HAL_TIMEx_ConfigBreakDeadTime(&htim1, &sBreakDeadTimeConfig) != HAL_OK)
  {
    Error_Handler();
  }
  HAL_TIM_MspPostInit(&htim1);

}

static void MX_TIM2_Init(void)
{

  TIM_ClockConfigTypeDef sClockSourceConfig = {0};
  TIM_MasterConfigTypeDef sMasterConfig = {0};

  htim2.Instance = TIM2;
  htim2.Init.Prescaler = 0;
  htim2.Init.CounterMode = TIM_COUNTERMODE_UP;
  htim2.Init.Period = 4294967295;
  htim2.Init.ClockDivision = TIM_CLOCKDIVISION_DIV1;
  htim2.Init.AutoReloadPreload = TIM_AUTORELOAD_PRELOAD_DISABLE;
  if (HAL_TIM_Base_Init(&htim2) != HAL_OK)
  {
    Error_Handler();
  }
  sClockSourceConfig.ClockSource = TIM_CLOCKSOURCE_ETRMODE2;
  sClockSourceConfig.ClockPolarity = TIM_CLOCKPOLARITY_NONINVERTED;
  sClockSourceConfig.ClockPrescaler = TIM_CLOCKPRESCALER_DIV1;
  sClockSourceConfig.ClockFilter = 0;
  if (HAL_TIM_ConfigClockSource(&htim2, &sClockSourceConfig) != HAL_OK)
  {
    Error_Handler();
  }
  sMasterConfig.MasterOutputTrigger = TIM_TRGO_RESET;
  sMasterConfig.MasterSlaveMode = TIM_MASTERSLAVEMODE_DISABLE;
  if (HAL_TIMEx_MasterConfigSynchronization(&htim2, &sMasterConfig) != HAL_OK)
  {
    Error_Handler();
  }

}

static void MX_TIM3_Init(void)
{

  TIM_MasterConfigTypeDef sMasterConfig = {0};
  TIM_OC_InitTypeDef sConfigOC = {0};

  htim3.Instance = TIM3;
  htim3.Init.Prescaler = 0;
  htim3.Init.CounterMode = TIM_COUNTERMODE_UP;
  htim3.Init.Period = 65535;
  htim3.Init.ClockDivision = TIM_CLOCKDIVISION_DIV1;
  htim3.Init.AutoReloadPreload = TIM_AUTORELOAD_PRELOAD_DISABLE;
  if (HAL_TIM_PWM_Init(&htim3) != HAL_OK)
  {
    Error_Handler();
  }
  sMasterConfig.MasterOutputTrigger = TIM_TRGO_RESET;
  sMasterConfig.MasterSlaveMode = TIM_MASTERSLAVEMODE_DISABLE;
  if (HAL_TIMEx_MasterConfigSynchronization(&htim3, &sMasterConfig) != HAL_OK)
  {
    Error_Handler();
  }
  sConfigOC.OCMode = TIM_OCMODE_PWM1;
  sConfigOC.Pulse = 0;
  sConfigOC.OCPolarity = TIM_OCPOLARITY_HIGH;
  sConfigOC.OCFastMode = TIM_OCFAST_DISABLE;
  if (HAL_TIM_PWM_ConfigChannel(&htim3, &sConfigOC, TIM_CHANNEL_2) != HAL_OK)
  {
    Error_Handler();
  }
  HAL_TIM_MspPostInit(&htim3);

}

static void MX_TIM4_Init(void)
{

  TIM_ClockConfigTypeDef sClockSourceConfig = {0};
  TIM_MasterConfigTypeDef sMasterConfig = {0};

  htim4.Instance = TIM4;
  htim4.Init.Prescaler = 0;
  htim4.Init.CounterMode = TIM_COUNTERMODE_UP;
  htim4.Init.Period = 65535;
  htim4.Init.ClockDivision = TIM_CLOCKDIVISION_DIV1;
  htim4.Init.AutoReloadPreload = TIM_AUTORELOAD_PRELOAD_DISABLE;
  if (HAL_TIM_Base_Init(&htim4) != HAL_OK)
  {
    Error_Handler();
  }
  sClockSourceConfig.ClockSource = TIM_CLOCKSOURCE_ETRMODE2;
  sClockSourceConfig.ClockPolarity = TIM_CLOCKPOLARITY_NONINVERTED;
  sClockSourceConfig.ClockPrescaler = TIM_CLOCKPRESCALER_DIV1;
  sClockSourceConfig.ClockFilter = 0;
  if (HAL_TIM_ConfigClockSource(&htim4, &sClockSourceConfig) != HAL_OK)
  {
    Error_Handler();
  }
  sMasterConfig.MasterOutputTrigger = TIM_TRGO_RESET;
  sMasterConfig.MasterSlaveMode = TIM_MASTERSLAVEMODE_DISABLE;
  if (HAL_TIMEx_MasterConfigSynchronization(&htim4, &sMasterConfig) != HAL_OK)
  {
    Error_Handler();
  }

}

static void MX_UART5_Init(void)
{

  huart5.Instance = UART5;
  huart5.Init.BaudRate = 9600;
  huart5.Init.WordLength = UART_WORDLENGTH_8B;
  huart5.Init.StopBits = UART_STOPBITS_1;
  huart5.Init.Parity = UART_PARITY_NONE;
  huart5.Init.Mode = UART_MODE_TX_RX;
  huart5.Init.HwFlowCtl = UART_HWCONTROL_NONE;
  huart5.Init.OverSampling = UART_OVERSAMPLING_16;
  huart5.Init.OneBitSampling = UART_ONE_BIT_SAMPLE_DISABLE;
  huart5.Init.ClockPrescaler = UART_PRESCALER_DIV1;
  huart5.AdvancedInit.AdvFeatureInit = UART_ADVFEATURE_NO_INIT;
  if (HAL_RS485Ex_Init(&huart5, UART_DE_POLARITY_HIGH, 0, 0) != HAL_OK)
  {
    Error_Handler();
  }
  if (HAL_UARTEx_SetTxFifoThreshold(&huart5, UART_TXFIFO_THRESHOLD_1_8) != HAL_OK)
  {
    Error_Handler();
  }
  if (HAL_UARTEx_SetRxFifoThreshold(&huart5, UART_RXFIFO_THRESHOLD_1_4) != HAL_OK)
  {
    Error_Handler();
  }
  if (HAL_UARTEx_EnableFifoMode(&huart5) != HAL_OK)
  {
    Error_Handler();
  }

}

static void MX_USART3_UART_Init(void)
{

  huart3.Instance = USART3;
  huart3.Init.BaudRate = 115200;
  huart3.Init.WordLength = UART_WORDLENGTH_8B;
  huart3.Init.StopBits = UART_STOPBITS_1;
  huart3.Init.Parity = UART_PARITY_NONE;
  huart3.Init.Mode = UART_MODE_TX_RX;
  huart3.Init.HwFlowCtl = UART_HWCONTROL_NONE;
  huart3.Init.OverSampling = UART_OVERSAMPLING_16;
  huart3.Init.OneBitSampling = UART_ONE_BIT_SAMPLE_DISABLE;
  huart3.Init.ClockPrescaler = UART_PRESCALER_DIV1;
  huart3.AdvancedInit.AdvFeatureInit = UART_ADVFEATURE_NO_INIT;
  if (HAL_UART_Init(&huart3) != HAL_OK)
  {
    Error_Handler();
  }
  if (HAL_UARTEx_SetTxFifoThreshold(&huart3, UART_TXFIFO_THRESHOLD_1_8) != HAL_OK)
  {
    Error_Handler();
  }
  if (HAL_UARTEx_SetRxFifoThreshold(&huart3, UART_RXFIFO_THRESHOLD_1_8) != HAL_OK)
  {
    Error_Handler();
  }
  if (HAL_UARTEx_EnableFifoMode(&huart3) != HAL_OK)
  {
    Error_Handler();
  }

}

static void MX_DMA_Init(void)
{

  /* DMA controller clock enable */
  __HAL_RCC_DMAMUX1_CLK_ENABLE();
  __HAL_RCC_DMA1_CLK_ENABLE();

  /* DMA interrupt init */
  /* DMA1_Channel1_IRQn interrupt configuration */
  HAL_NVIC_SetPriority(DMA1_Channel1_IRQn, 0, 0);
  HAL_NVIC_EnableIRQ(DMA1_Channel1_IRQn);
  /* DMA1_Channel2_IRQn interrupt configuration */
  HAL_NVIC_SetPriority(DMA1_Channel2_IRQn, 0, 0);
  HAL_NVIC_EnableIRQ(DMA1_Channel2_IRQn);
  /* DMA1_Channel3_IRQn interrupt configuration */
  HAL_NVIC_SetPriority(DMA1_Channel3_IRQn, 5, 0);
  HAL_NVIC_EnableIRQ(DMA1_Channel3_IRQn);
  /* DMA1_Channel4_IRQn interrupt configuration */
  HAL_NVIC_SetPriority(DMA1_Channel4_IRQn, 5, 0);
  HAL_NVIC_EnableIRQ(DMA1_Channel4_IRQn);
  /* DMA1_Channel5_IRQn interrupt configuration */
  HAL_NVIC_SetPriority(DMA1_Channel5_IRQn, 5, 0);
  HAL_NVIC_EnableIRQ(DMA1_Channel5_IRQn);

}

static void MX_GPIO_Init(void)
{
  GPIO_InitTypeDef GPIO_InitStruct = {0};

  /* GPIO Ports Clock Enable */
  __HAL_RCC_GPIOC_CLK_ENABLE();
  __HAL_RCC_GPIOF_CLK_ENABLE();
  __HAL_RCC_GPIOA_CLK_ENABLE();
  __HAL_RCC_GPIOB_CLK_ENABLE();
  __HAL_RCC_GPIOD_CLK_ENABLE();

  /*Configure GPIO pin Output Level */
  HAL_GPIO_WritePin(GPIOC, GPIO_PIN_13|GPIO_PIN_14|GPIO_PIN_15|GPIO_PIN_0
                          |GPIO_PIN_4, GPIO_PIN_RESET);

  /*Configure GPIO pin Output Level */
  HAL_GPIO_WritePin(GPIOA, GPIO_PIN_3, GPIO_PIN_RESET);

  /*Configure GPIO pin Output Level */
  HAL_GPIO_WritePin(GPIOB, GPIO_PIN_0|GPIO_PIN_1|GPIO_PIN_10|GPIO_PIN_14
                          |GPIO_PIN_7, GPIO_PIN_RESET);

  /*Configure GPIO pins : PC13 PC14 PC15 PC0
                           PC4 */
  GPIO_InitStruct.Pin = GPIO_PIN_13|GPIO_PIN_14|GPIO_PIN_15|GPIO_PIN_0
                          |GPIO_PIN_4;
  GPIO_InitStruct.Mode = GPIO_MODE_OUTPUT_PP;
  GPIO_InitStruct.Pull = GPIO_NOPULL;
  GPIO_InitStruct.Speed = GPIO_SPEED_FREQ_LOW;
  HAL_GPIO_Init(GPIOC, &GPIO_InitStruct);

  /*Configure GPIO pin : PC3 */
  GPIO_InitStruct.Pin = GPIO_PIN_3;
  GPIO_InitStruct.Mode = GPIO_MODE_IT_FALLING;
  GPIO_InitStruct.Pull = GPIO_NOPULL;
  HAL_GPIO_Init(GPIOC, &GPIO_InitStruct);

  /*Configure GPIO pin : PA2 */
  GPIO_InitStruct.Pin = GPIO_PIN_2;
  GPIO_InitStruct.Mode = GPIO_MODE_IT_FALLING;
  GPIO_InitStruct.Pull = GPIO_NOPULL;
  HAL_GPIO_Init(GPIOA, &GPIO_InitStruct);

  /*Configure GPIO pin : PA3 */
  GPIO_InitStruct.Pin = GPIO_PIN_3;
  GPIO_InitStruct.Mode = GPIO_MODE_OUTPUT_PP;
  GPIO_InitStruct.Pull = GPIO_NOPULL;
  GPIO_InitStruct.Speed = GPIO_SPEED_FREQ_LOW;
  HAL_GPIO_Init(GPIOA, &GPIO_InitStruct);

  /*Configure GPIO pins : PB0 PB1 PB10 PB14
                           PB7 */
  GPIO_InitStruct.Pin = GPIO_PIN_0|GPIO_PIN_1|GPIO_PIN_10|GPIO_PIN_14
                          |GPIO_PIN_7;
  GPIO_InitStruct.Mode = GPIO_MODE_OUTPUT_PP;
  GPIO_InitStruct.Pull = GPIO_NOPULL;
  GPIO_InitStruct.Speed = GPIO_SPEED_FREQ_LOW;
  HAL_GPIO_Init(GPIOB, &GPIO_InitStruct);

  /*Configure GPIO pin : PB11 */
  GPIO_InitStruct.Pin = GPIO_PIN_11;
  GPIO_InitStruct.Mode = GPIO_MODE_IT_RISING;
  GPIO_InitStruct.Pull = GPIO_PULLUP;
  HAL_GPIO_Init(GPIOB, &GPIO_InitStruct);

  /*Configure GPIO pin : PA11 */
  GPIO_InitStruct.Pin = GPIO_PIN_11;
  GPIO_InitStruct.Mode = GPIO_MODE_AF_PP;
  GPIO_InitStruct.Pull = GPIO_NOPULL;
  GPIO_InitStruct.Speed = GPIO_SPEED_FREQ_LOW;
  GPIO_InitStruct.Alternate = GPIO_AF9_FDCAN1;
  HAL_GPIO_Init(GPIOA, &GPIO_InitStruct);

  /*Configure GPIO pin : PA12 */
  GPIO_InitStruct.Pin = GPIO_PIN_12;
  GPIO_InitStruct.Mode = GPIO_MODE_IT_RISING;
  GPIO_InitStruct.Pull = GPIO_PULLUP;
  HAL_GPIO_Init(GPIOA, &GPIO_InitStruct);

  /*Configure GPIO pin : PA15 */
  GPIO_InitStruct.Pin = GPIO_PIN_15;
  GPIO_InitStruct.Mode = GPIO_MODE_INPUT;
  GPIO_InitStruct.Pull = GPIO_PULLDOWN;
  HAL_GPIO_Init(GPIOA, &GPIO_InitStruct);

  /*Configure GPIO pin : PB9 */
  GPIO_InitStruct.Pin = GPIO_PIN_9;
  GPIO_InitStruct.Mode = GPIO_MODE_AF_PP;
  GPIO_InitStruct.Pull = GPIO_NOPULL;
  GPIO_InitStruct.Speed = GPIO_SPEED_FREQ_LOW;
  GPIO_InitStruct.Alternate = GPIO_AF9_FDCAN1;
  HAL_GPIO_Init(GPIOB, &GPIO_InitStruct);

  /* EXTI interrupt init*/
  HAL_NVIC_SetPriority(EXTI2_IRQn, 0, 0);
  HAL_NVIC_EnableIRQ(EXTI2_IRQn);

  HAL_NVIC_SetPriority(EXTI3_IRQn, 0, 0);
  HAL_NVIC_EnableIRQ(EXTI3_IRQn);

  HAL_NVIC_SetPriority(EXTI15_10_IRQn, 0, 0);
  HAL_NVIC_EnableIRQ(EXTI15_10_IRQn);

}

/* USER CODE BEGIN 4 */

/**
  * @brief  Configures the FDCAN.
  * @param  None
  * @retval None
  */
static void FDCAN_Config(void)
{
  /* Configure global filter:
     Filter all remote frames with STD and EXT ID
     Reject non matching frames with STD ID and EXT ID */
  if (HAL_FDCAN_ConfigGlobalFilter(&hfdcan2, FDCAN_REJECT, FDCAN_REJECT, FDCAN_FILTER_REMOTE, FDCAN_FILTER_REMOTE) != HAL_OK)
  {
    Error_Handler();
  }

  /* Start the FDCAN module */
  if (HAL_FDCAN_Start(&hfdcan2) != HAL_OK)
  {
    Error_Handler();
  }

  // use polling for now
//  if (HAL_FDCAN_ActivateNotification(&hfdcan2, FDCAN_IT_RX_FIFO0_NEW_MESSAGE, 0) != HAL_OK)
//  {
//    Error_Handler();
//  }

}

/**
  * @brief  Rx FIFO 0 callback.
  * @param  hfdcan: pointer to an FDCAN_HandleTypeDef structure that contains
  *         the configuration information for the specified FDCAN.
  * @param  RxFifo0ITs: indicates which Rx FIFO 0 interrupts are signalled.
  *         This parameter can be any combination of @arg FDCAN_Rx_Fifo0_Interrupts.
  * @retval None
  */
void HAL_FDCAN_RxFifo0Callback(FDCAN_HandleTypeDef *hfdcan, uint32_t RxFifo0ITs)
{
//  if((RxFifo0ITs & FDCAN_IT_RX_FIFO0_NEW_MESSAGE) != RESET)
//  {
//    /* Retrieve Rx messages from RX FIFO0 */
//    if (HAL_FDCAN_GetRxMessage(hfdcan, FDCAN_RX_FIFO0, &RxHeader, RxData) != HAL_OK)
//    {
//    Error_Handler();
//    }
//
//    if ((RxHeader.Identifier == 0x40D) && (RxHeader.IdType == FDCAN_STANDARD_ID))// && (RxHeader.DataLength == FDCAN_DLC_BYTES_8))
//    {
//    	uSend("\nRX ID: ");
//    	uSendInt(RxHeader.Identifier);
//    	uSend("\nRX DLC: ");
//    	uSendInt(RxHeader.DataLength);
//
//    	//csc_cell_volt_min_max_t *csc_cell_volt_min_max = &RxData[0];
//
//    	uSend("\ncell_voltage_max_mV: ");
//    	uSendInt(((csc_cell_volt_min_max_t *)RxData)->cell_voltage_max_mV);
//    } else {
//    	uSend("invalid CAN msg\n");
//    }
//  }
}

/* USER CODE END 4 */

void Error_Handler(void)
{
  /* USER CODE BEGIN Error_Handler_Debug */
  /* User can add his own implementation to report the HAL error return state */
  __disable_irq();
  while (1)
  {
	  shutdownAll();
	  uSend("Error_Handler\n");
  }
  /* USER CODE END Error_Handler_Debug */
}
